// *************************************************************************** *
// *                                                                           *
// *                      Mentor Graphics Corporation                          *
// *                          All rights reserved                              *
// *                                                                           *
// *************************************************************************** *
// *                                                                           *
// * Description:         CANDB File                                           *
// * Generated at:        2021-02-26 13:32                                     *
// * System:              SPA4710_Final2                                       *
// * Variant:             ConfigurationsSPA3AD                                 *
// * Network:             Mid3Can                                              *
// *                                                                           *
// *************************************************************************** *
// *                                                                           *
// *             THIS CONFIGURATION MIGHT CONTAIN SOME ERRORS                  *
// *              IF THE INPUT MODEL WAS NOT PROPERLY FORMED!                  *
// *                    Do Not Use this File directly!                         *
// *                                                                           *
// *************************************************************************** *
VERSION "Mid3Can"

NS_ :

BS_ :

BU_ :  ETC SSM VCU1 VIM VIMB

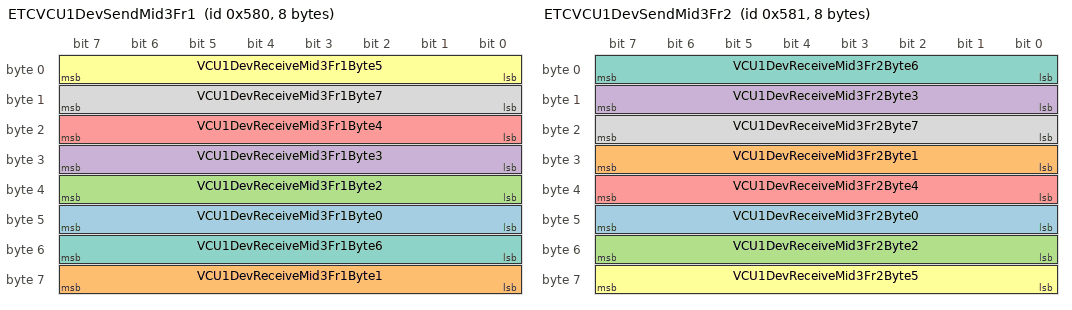
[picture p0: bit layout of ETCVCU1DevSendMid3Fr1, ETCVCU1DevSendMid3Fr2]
BO_ 1408 ETCVCU1DevSendMid3Fr1 : 8 ETC
 SG_ VCU1DevReceiveMid3Fr1Byte0 : 47|8@0+ (1.0,0.0) [0.0|255.0] "Unitless" VCU1
 SG_ VCU1DevReceiveMid3Fr1Byte1 : 63|8@0+ (1.0,0.0) [0.0|255.0] "Unitless" VCU1
 SG_ VCU1DevReceiveMid3Fr1Byte2 : 39|8@0+ (1.0,0.0) [0.0|255.0] "Unitless" VCU1
 SG_ VCU1DevReceiveMid3Fr1Byte3 : 31|8@0+ (1.0,0.0) [0.0|255.0] "Unitless" VCU1
 SG_ VCU1DevReceiveMid3Fr1Byte4 : 23|8@0+ (1.0,0.0) [0.0|255.0] "Unitless" VCU1
 SG_ VCU1DevReceiveMid3Fr1Byte5 : 7|8@0+ (1.0,0.0) [0.0|255.0] "Unitless" VCU1
 SG_ VCU1DevReceiveMid3Fr1Byte6 : 55|8@0+ (1.0,0.0) [0.0|255.0] "Unitless" VCU1
 SG_ VCU1DevReceiveMid3Fr1Byte7 : 15|8@0+ (1.0,0.0) [0.0|255.0] "Unitless" VCU1

BO_ 1409 ETCVCU1DevSendMid3Fr2 : 8 ETC
 SG_ VCU1DevReceiveMid3Fr2Byte0 : 47|8@0+ (1.0,0.0) [0.0|255.0] "Unitless" VCU1
 SG_ VCU1DevReceiveMid3Fr2Byte1 : 31|8@0+ (1.0,0.0) [0.0|255.0] "Unitless" VCU1
 SG_ VCU1DevReceiveMid3Fr2Byte2 : 55|8@0+ (1.0,0.0) [0.0|255.0] "Unitless" VCU1
 SG_ VCU1DevReceiveMid3Fr2Byte3 : 15|8@0+ (1.0,0.0) [0.0|255.0] "Unitless" VCU1
 SG_ VCU1DevReceiveMid3Fr2Byte4 : 39|8@0+ (1.0,0.0) [0.0|255.0] "Unitless" VCU1
 SG_ VCU1DevReceiveMid3Fr2Byte5 : 63|8@0+ (1.0,0.0) [0.0|255.0] "Unitless" VCU1
 SG_ VCU1DevReceiveMid3Fr2Byte6 : 7|8@0+ (1.0,0.0) [0.0|255.0] "Unitless" VCU1
 SG_ VCU1DevReceiveMid3Fr2Byte7 : 23|8@0+ (1.0,0.0) [0.0|255.0] "Unitless" VCU1

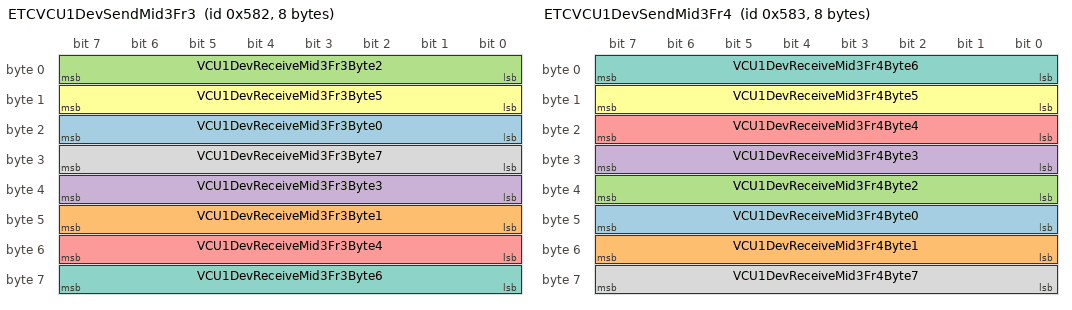
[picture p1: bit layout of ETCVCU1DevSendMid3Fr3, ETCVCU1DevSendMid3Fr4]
BO_ 1410 ETCVCU1DevSendMid3Fr3 : 8 ETC
 SG_ VCU1DevReceiveMid3Fr3Byte0 : 23|8@0+ (1.0,0.0) [0.0|255.0] "Unitless" VCU1
 SG_ VCU1DevReceiveMid3Fr3Byte1 : 47|8@0+ (1.0,0.0) [0.0|255.0] "Unitless" VCU1
 SG_ VCU1DevReceiveMid3Fr3Byte2 : 7|8@0+ (1.0,0.0) [0.0|255.0] "Unitless" VCU1
 SG_ VCU1DevReceiveMid3Fr3Byte3 : 39|8@0+ (1.0,0.0) [0.0|255.0] "Unitless" VCU1
 SG_ VCU1DevReceiveMid3Fr3Byte4 : 55|8@0+ (1.0,0.0) [0.0|255.0] "Unitless" VCU1
 SG_ VCU1DevReceiveMid3Fr3Byte5 : 15|8@0+ (1.0,0.0) [0.0|255.0] "Unitless" VCU1
 SG_ VCU1DevReceiveMid3Fr3Byte6 : 63|8@0+ (1.0,0.0) [0.0|255.0] "Unitless" VCU1
 SG_ VCU1DevReceiveMid3Fr3Byte7 : 31|8@0+ (1.0,0.0) [0.0|255.0] "Unitless" VCU1

BO_ 1411 ETCVCU1DevSendMid3Fr4 : 8 ETC
 SG_ VCU1DevReceiveMid3Fr4Byte0 : 47|8@0+ (1.0,0.0) [0.0|255.0] "Unitless" VCU1
 SG_ VCU1DevReceiveMid3Fr4Byte1 : 55|8@0+ (1.0,0.0) [0.0|255.0] "Unitless" VCU1
 SG_ VCU1DevReceiveMid3Fr4Byte2 : 39|8@0+ (1.0,0.0) [0.0|255.0] "Unitless" VCU1
 SG_ VCU1DevReceiveMid3Fr4Byte3 : 31|8@0+ (1.0,0.0) [0.0|255.0] "Unitless" VCU1
 SG_ VCU1DevReceiveMid3Fr4Byte4 : 23|8@0+ (1.0,0.0) [0.0|255.0] "Unitless" VCU1
 SG_ VCU1DevReceiveMid3Fr4Byte5 : 15|8@0+ (1.0,0.0) [0.0|255.0] "Unitless" VCU1
 SG_ VCU1DevReceiveMid3Fr4Byte6 : 7|8@0+ (1.0,0.0) [0.0|255.0] "Unitless" VCU1
 SG_ VCU1DevReceiveMid3Fr4Byte7 : 63|8@0+ (1.0,0.0) [0.0|255.0] "Unitless" VCU1

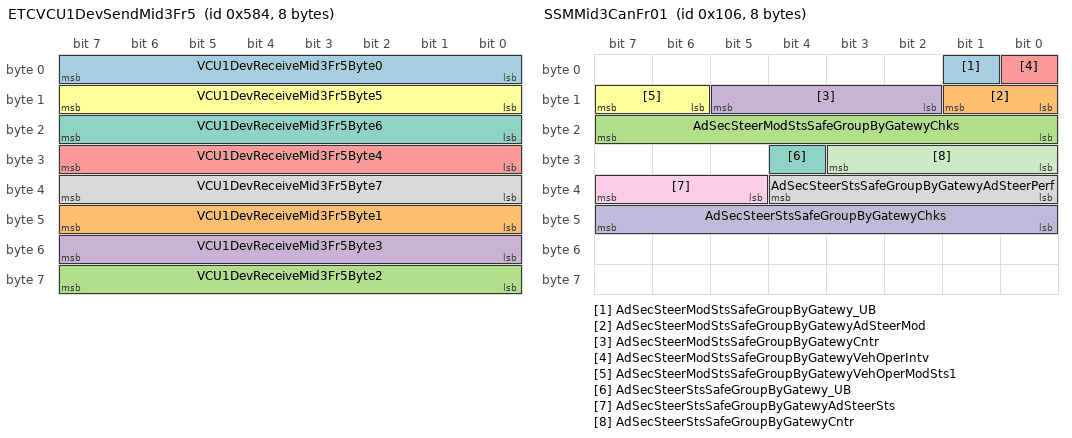
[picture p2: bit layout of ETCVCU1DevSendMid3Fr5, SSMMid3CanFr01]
BO_ 1412 ETCVCU1DevSendMid3Fr5 : 8 ETC
 SG_ VCU1DevReceiveMid3Fr5Byte0 : 7|8@0+ (1.0,0.0) [0.0|255.0] "Unitless" VCU1
 SG_ VCU1DevReceiveMid3Fr5Byte1 : 47|8@0+ (1.0,0.0) [0.0|255.0] "Unitless" VCU1
 SG_ VCU1DevReceiveMid3Fr5Byte2 : 63|8@0+ (1.0,0.0) [0.0|255.0] "Unitless" VCU1
 SG_ VCU1DevReceiveMid3Fr5Byte3 : 55|8@0+ (1.0,0.0) [0.0|255.0] "Unitless" VCU1
 SG_ VCU1DevReceiveMid3Fr5Byte4 : 31|8@0+ (1.0,0.0) [0.0|255.0] "Unitless" VCU1
 SG_ VCU1DevReceiveMid3Fr5Byte5 : 15|8@0+ (1.0,0.0) [0.0|255.0] "Unitless" VCU1
 SG_ VCU1DevReceiveMid3Fr5Byte6 : 23|8@0+ (1.0,0.0) [0.0|255.0] "Unitless" VCU1
 SG_ VCU1DevReceiveMid3Fr5Byte7 : 39|8@0+ (1.0,0.0) [0.0|255.0] "Unitless" VCU1

BO_ 262 SSMMid3CanFr01 : 8 SSM
 SG_ AdSecSteerModStsSafeGroupByGatewy_UB : 1|1@0+ (1,0) [0|1] "" VCU1
 SG_ AdSecSteerModStsSafeGroupByGatewyAdSteerMod : 9|2@0+ (1,0) [0|3] "" VCU1
 SG_ AdSecSteerModStsSafeGroupByGatewyChks : 23|8@0+ (1.0,0.0) [0.0|255.0] "Unitless" VCU1
 SG_ AdSecSteerModStsSafeGroupByGatewyCntr : 13|4@0+ (1.0,0.0) [0.0|15.0] "Unitless" VCU1
 SG_ AdSecSteerModStsSafeGroupByGatewyVehOperIntv : 0|1@0+ (1,0) [0|1] "" VCU1
 SG_ AdSecSteerModStsSafeGroupByGatewyVehOperModSts1 : 15|2@0+ (1,0) [0|3] "" VCU1
 SG_ AdSecSteerStsSafeGroupByGatewy_UB : 28|1@0+ (1,0) [0|1] "" VCU1
 SG_ AdSecSteerStsSafeGroupByGatewyAdSteerPerf : 36|5@0+ (1,0) [0|31] "" VCU1
 SG_ AdSecSteerStsSafeGroupByGatewyAdSteerSts : 39|3@0+ (1,0) [0|7] "" VCU1
 SG_ AdSecSteerStsSafeGroupByGatewyChks : 47|8@0+ (1.0,0.0) [0.0|255.0] "Unitless" VCU1
 SG_ AdSecSteerStsSafeGroupByGatewyCntr : 27|4@0+ (1.0,0.0) [0.0|15.0] "Unitless" VCU1

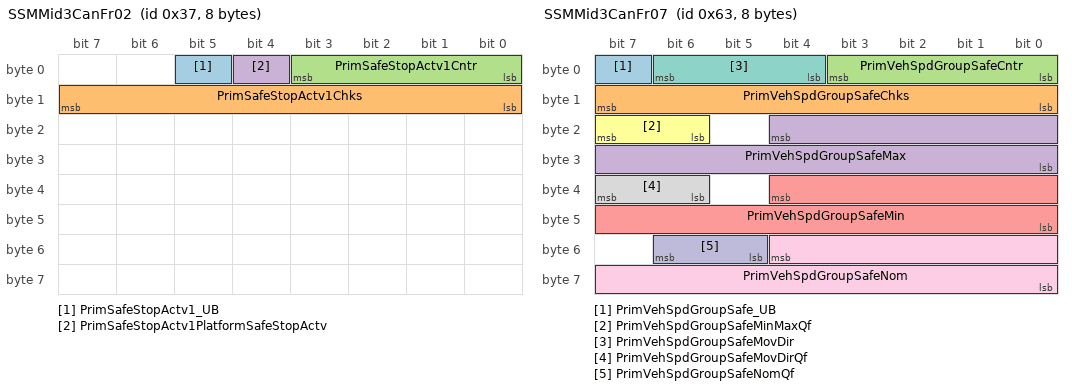
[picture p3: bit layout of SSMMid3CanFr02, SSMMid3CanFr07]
BO_ 55 SSMMid3CanFr02 : 8 SSM
 SG_ PrimSafeStopActv1_UB : 5|1@0+ (1,0) [0|1] "" VCU1
 SG_ PrimSafeStopActv1Chks : 15|8@0+ (1.0,0.0) [0.0|255.0] "Unitless" VCU1
 SG_ PrimSafeStopActv1Cntr : 3|4@0+ (1.0,0.0) [0.0|15.0] "Unitless" VCU1
 SG_ PrimSafeStopActv1PlatformSafeStopActv : 4|1@0+ (1,0) [0|1] "" VCU1

BO_ 99 SSMMid3CanFr07 : 8 SSM
 SG_ PrimVehSpdGroupSafe_UB : 7|1@0+ (1,0) [0|1] "" VCU1,VIM
 SG_ PrimVehSpdGroupSafeChks : 15|8@0+ (1.0,0.0) [0.0|255.0] "Unitless" VCU1,VIM
 SG_ PrimVehSpdGroupSafeCntr : 3|4@0+ (1.0,0.0) [0.0|15.0] "Unitless" VCU1,VIM
 SG_ PrimVehSpdGroupSafeMax : 20|13@0+ (0.01,0.0) [0.0|81.91] "m/s" VCU1,VIM
 SG_ PrimVehSpdGroupSafeMin : 36|13@0+ (0.01,0.0) [0.0|81.91] "m/s" VCU1,VIM
 SG_ PrimVehSpdGroupSafeMinMaxQf : 23|2@0+ (1,0) [0|3] "" VCU1,VIM
 SG_ PrimVehSpdGroupSafeMovDir : 6|3@0+ (1,0) [0|7] "" VCU1,VIM
 SG_ PrimVehSpdGroupSafeMovDirQf : 39|2@0+ (1,0) [0|3] "" VCU1,VIM
 SG_ PrimVehSpdGroupSafeNom : 52|13@0+ (0.01,0.0) [0.0|81.91] "m/s" VCU1,VIM
 SG_ PrimVehSpdGroupSafeNomQf : 54|2@0+ (1,0) [0|3] "" VCU1,VIM

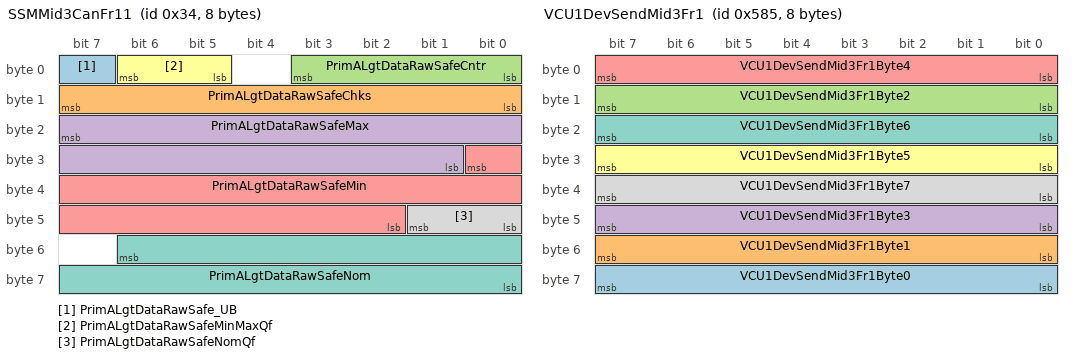
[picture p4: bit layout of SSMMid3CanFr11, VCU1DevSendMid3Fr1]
BO_ 52 SSMMid3CanFr11 : 8 SSM
 SG_ PrimALgtDataRawSafe_UB : 7|1@0+ (1,0) [0|1] "" VCU1,VIM
 SG_ PrimALgtDataRawSafeChks : 15|8@0+ (1.0,0.0) [0.0|255.0] "Unitless" VCU1,VIM
 SG_ PrimALgtDataRawSafeCntr : 3|4@0+ (1.0,0.0) [0.0|15.0] "Unitless" VCU1,VIM
 SG_ PrimALgtDataRawSafeMax : 23|15@0+ (0.001,-16.384) [-16.384|16.383000000000003] "m/s^2" VCU1,VIM
 SG_ PrimALgtDataRawSafeMin : 24|15@0+ (0.001,-16.384) [-16.384|16.383000000000003] "m/s^2" VCU1,VIM
 SG_ PrimALgtDataRawSafeMinMaxQf : 6|2@0+ (1,0) [0|3] "" VCU1,VIM
 SG_ PrimALgtDataRawSafeNom : 54|15@0+ (0.001,-16.384) [-16.384|16.383000000000003] "m/s^2" VCU1,VIM
 SG_ PrimALgtDataRawSafeNomQf : 41|2@0+ (1,0) [0|3] "" VCU1,VIM

BO_ 1287 SsmMid3CanNmFr : 8 SSM
 SG_ Body_SSM : 21|1@0+ (1,0) [0|0] "" VIM
 SG_ Brake_SSM : 33|1@0+ (1,0) [0|0] "" VIM
 SG_ Diesel_SSM : 32|1@0+ (1,0) [0|0] "" VIM
 SG_ Hazard_SSM : 18|1@0+ (1,0) [0|0] "" VIM
 SG_ InfotainmentAndHMI_SSM : 22|1@0+ (1,0) [0|0] "" VIM
 SG_ PNCCharging_SSM : 25|1@0+ (1,0) [0|0] "" VIM
 SG_ PNCDriverinfo_SSM : 16|1@0+ (1,0) [0|0] "" VIM
 SG_ PNCDriverinfoPoll_SSM : 31|1@0+ (1,0) [0|0] "" VIM
 SG_ PNCDriving_SSM : 27|1@0+ (1,0) [0|0] "" VIM
 SG_ PNCEntrance_SSM : 23|1@0+ (1,0) [0|0] "" VIM
 SG_ PNCGlobal_SSM : 29|1@0+ (1,0) [0|0] "" VIM
 SG_ PNCGSD_SSM : 30|1@0+ (1,0) [0|0] "" VIM
 SG_ PNCHVEnergyStorage_SSM : 35|1@0+ (1,0) [0|0] "" VIM
 SG_ PNCLocking_SSM : 17|1@0+ (1,0) [0|0] "" VIM
 SG_ PNCPreClimatization_SSM : 26|1@0+ (1,0) [0|0] "" VIM
 SG_ PNCSpare1_SSM : 39|1@0+ (1,0) [0|0] "" VIM
 SG_ PNCSpare2_SSM : 38|1@0+ (1,0) [0|0] "" VIM
 SG_ PNCSpare3_SSM : 37|1@0+ (1,0) [0|0] "" VIM
 SG_ PNCSpare4_SSM : 36|1@0+ (1,0) [0|0] "" VIM
 SG_ PNCStart_SSM : 24|1@0+ (1,0) [0|0] "" VIM
 SG_ PNCTrailerCaravan_SSM : 28|1@0+ (1,0) [0|0] "" VIM
 SG_ VehicleAPI_SSM : 34|1@0+ (1,0) [0|0] "" VIM
 SG_ Visibility_SSM : 20|1@0+ (1,0) [0|0] "" VIM
 SG_ WarningSounds_SSM : 19|1@0+ (1,0) [0|0] "" VIM
 SG_ NM_PNI_SSM : 14|1@0+ (1,0) [0|0] "" VIM
 SG_ NM_AW_SSM : 12|1@0+ (1,0) [0|0] "" VIM
 SG_ NM_CS_SSM : 11|1@0+ (1,0) [0|0] "" VIM
 SG_ NM_RMR_SSM : 8|1@0+ (1,0) [0|0] "" VIM
 SG_ NM_NodeID_SSM : 7|8@0+ (1,0) [0|0] "" VIM

BO_ 1413 VCU1DevSendMid3Fr1 : 8 VCU1
 SG_ VCU1DevSendMid3Fr1Byte0 : 63|8@0+ (1.0,0.0) [0.0|255.0] "Unitless" ETC
 SG_ VCU1DevSendMid3Fr1Byte1 : 55|8@0+ (1.0,0.0) [0.0|255.0] "Unitless" ETC
 SG_ VCU1DevSendMid3Fr1Byte2 : 15|8@0+ (1.0,0.0) [0.0|255.0] "Unitless" ETC
 SG_ VCU1DevSendMid3Fr1Byte3 : 47|8@0+ (1.0,0.0) [0.0|255.0] "Unitless" ETC
 SG_ VCU1DevSendMid3Fr1Byte4 : 7|8@0+ (1.0,0.0) [0.0|255.0] "Unitless" ETC
 SG_ VCU1DevSendMid3Fr1Byte5 : 31|8@0+ (1.0,0.0) [0.0|255.0] "Unitless" ETC
 SG_ VCU1DevSendMid3Fr1Byte6 : 23|8@0+ (1.0,0.0) [0.0|255.0] "Unitless" ETC
 SG_ VCU1DevSendMid3Fr1Byte7 : 39|8@0+ (1.0,0.0) [0.0|255.0] "Unitless" ETC

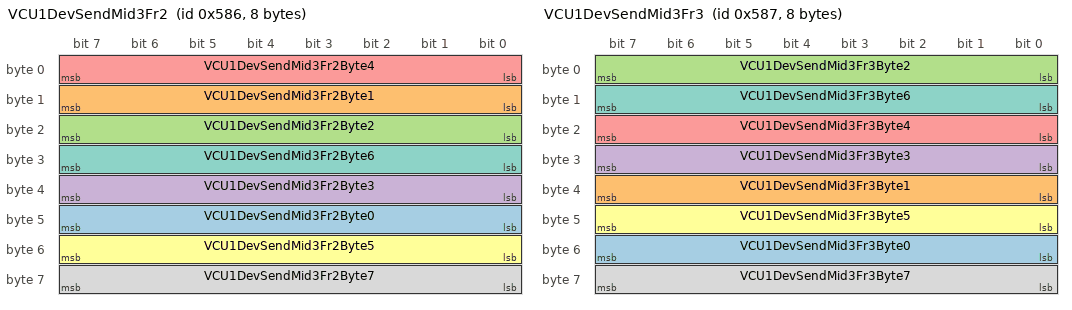
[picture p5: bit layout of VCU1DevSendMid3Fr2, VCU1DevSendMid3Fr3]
BO_ 1414 VCU1DevSendMid3Fr2 : 8 VCU1
 SG_ VCU1DevSendMid3Fr2Byte0 : 47|8@0+ (1.0,0.0) [0.0|255.0] "Unitless" ETC
 SG_ VCU1DevSendMid3Fr2Byte1 : 15|8@0+ (1.0,0.0) [0.0|255.0] "Unitless" ETC
 SG_ VCU1DevSendMid3Fr2Byte2 : 23|8@0+ (1.0,0.0) [0.0|255.0] "Unitless" ETC
 SG_ VCU1DevSendMid3Fr2Byte3 : 39|8@0+ (1.0,0.0) [0.0|255.0] "Unitless" ETC
 SG_ VCU1DevSendMid3Fr2Byte4 : 7|8@0+ (1.0,0.0) [0.0|255.0] "Unitless" ETC
 SG_ VCU1DevSendMid3Fr2Byte5 : 55|8@0+ (1.0,0.0) [0.0|255.0] "Unitless" ETC
 SG_ VCU1DevSendMid3Fr2Byte6 : 31|8@0+ (1.0,0.0) [0.0|255.0] "Unitless" ETC
 SG_ VCU1DevSendMid3Fr2Byte7 : 63|8@0+ (1.0,0.0) [0.0|255.0] "Unitless" ETC

BO_ 1415 VCU1DevSendMid3Fr3 : 8 VCU1
 SG_ VCU1DevSendMid3Fr3Byte0 : 55|8@0+ (1.0,0.0) [0.0|255.0] "Unitless" ETC
 SG_ VCU1DevSendMid3Fr3Byte1 : 39|8@0+ (1.0,0.0) [0.0|255.0] "Unitless" ETC
 SG_ VCU1DevSendMid3Fr3Byte2 : 7|8@0+ (1.0,0.0) [0.0|255.0] "Unitless" ETC
 SG_ VCU1DevSendMid3Fr3Byte3 : 31|8@0+ (1.0,0.0) [0.0|255.0] "Unitless" ETC
 SG_ VCU1DevSendMid3Fr3Byte4 : 23|8@0+ (1.0,0.0) [0.0|255.0] "Unitless" ETC
 SG_ VCU1DevSendMid3Fr3Byte5 : 47|8@0+ (1.0,0.0) [0.0|255.0] "Unitless" ETC
 SG_ VCU1DevSendMid3Fr3Byte6 : 15|8@0+ (1.0,0.0) [0.0|255.0] "Unitless" ETC
 SG_ VCU1DevSendMid3Fr3Byte7 : 63|8@0+ (1.0,0.0) [0.0|255.0] "Unitless" ETC

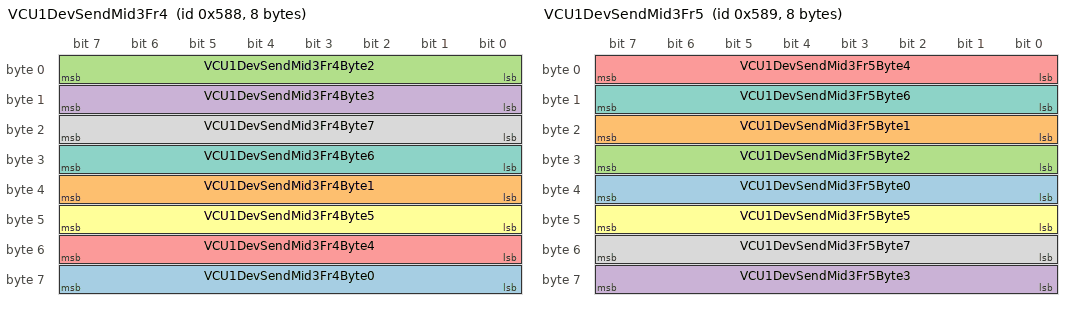
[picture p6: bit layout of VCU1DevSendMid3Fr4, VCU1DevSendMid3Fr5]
BO_ 1416 VCU1DevSendMid3Fr4 : 8 VCU1
 SG_ VCU1DevSendMid3Fr4Byte0 : 63|8@0+ (1.0,0.0) [0.0|255.0] "Unitless" ETC
 SG_ VCU1DevSendMid3Fr4Byte1 : 39|8@0+ (1.0,0.0) [0.0|255.0] "Unitless" ETC
 SG_ VCU1DevSendMid3Fr4Byte2 : 7|8@0+ (1.0,0.0) [0.0|255.0] "Unitless" ETC
 SG_ VCU1DevSendMid3Fr4Byte3 : 15|8@0+ (1.0,0.0) [0.0|255.0] "Unitless" ETC
 SG_ VCU1DevSendMid3Fr4Byte4 : 55|8@0+ (1.0,0.0) [0.0|255.0] "Unitless" ETC
 SG_ VCU1DevSendMid3Fr4Byte5 : 47|8@0+ (1.0,0.0) [0.0|255.0] "Unitless" ETC
 SG_ VCU1DevSendMid3Fr4Byte6 : 31|8@0+ (1.0,0.0) [0.0|255.0] "Unitless" ETC
 SG_ VCU1DevSendMid3Fr4Byte7 : 23|8@0+ (1.0,0.0) [0.0|255.0] "Unitless" ETC

BO_ 1417 VCU1DevSendMid3Fr5 : 8 VCU1
 SG_ VCU1DevSendMid3Fr5Byte0 : 39|8@0+ (1.0,0.0) [0.0|255.0] "Unitless" ETC
 SG_ VCU1DevSendMid3Fr5Byte1 : 23|8@0+ (1.0,0.0) [0.0|255.0] "Unitless" ETC
 SG_ VCU1DevSendMid3Fr5Byte2 : 31|8@0+ (1.0,0.0) [0.0|255.0] "Unitless" ETC
 SG_ VCU1DevSendMid3Fr5Byte3 : 63|8@0+ (1.0,0.0) [0.0|255.0] "Unitless" ETC
 SG_ VCU1DevSendMid3Fr5Byte4 : 7|8@0+ (1.0,0.0) [0.0|255.0] "Unitless" ETC
 SG_ VCU1DevSendMid3Fr5Byte5 : 47|8@0+ (1.0,0.0) [0.0|255.0] "Unitless" ETC
 SG_ VCU1DevSendMid3Fr5Byte6 : 15|8@0+ (1.0,0.0) [0.0|255.0] "Unitless" ETC
 SG_ VCU1DevSendMid3Fr5Byte7 : 55|8@0+ (1.0,0.0) [0.0|255.0] "Unitless" ETC

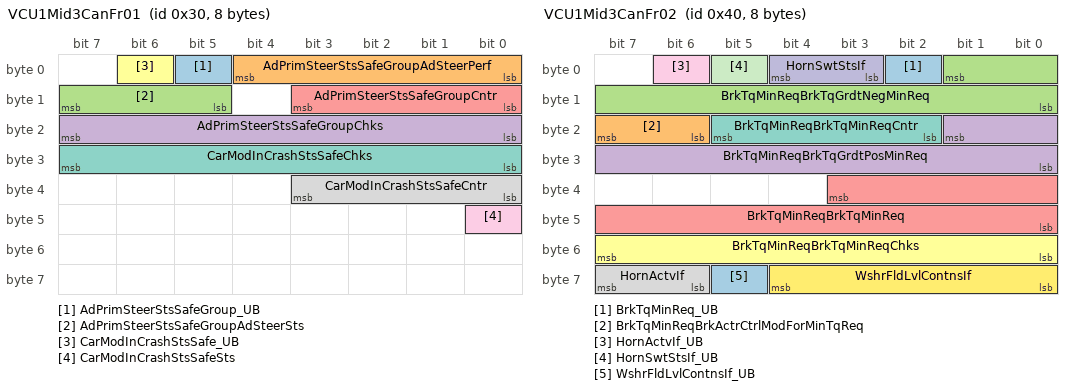
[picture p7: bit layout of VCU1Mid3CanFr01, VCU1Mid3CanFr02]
BO_ 48 VCU1Mid3CanFr01 : 8 VCU1
 SG_ AdPrimSteerStsSafeGroup_UB : 5|1@0+ (1,0) [0|1] "" VIM
 SG_ AdPrimSteerStsSafeGroupAdSteerPerf : 4|5@0+ (1,0) [0|31] "" VIM
 SG_ AdPrimSteerStsSafeGroupAdSteerSts : 15|3@0+ (1,0) [0|7] "" VIM
 SG_ AdPrimSteerStsSafeGroupChks : 23|8@0+ (1.0,0.0) [0.0|255.0] "Unitless" VIM
 SG_ AdPrimSteerStsSafeGroupCntr : 11|4@0+ (1.0,0.0) [0.0|15.0] "Unitless" VIM
 SG_ CarModInCrashStsSafe_UB : 6|1@0+ (1,0) [0|1] "" VIM,VIMB
 SG_ CarModInCrashStsSafeChks : 24|8@1+ (1.0,0.0) [0.0|255.0] "Unitless" VIM,VIMB
 SG_ CarModInCrashStsSafeCntr : 32|4@1+ (1.0,0.0) [0.0|15.0] "Unitless" VIM,VIMB
 SG_ CarModInCrashStsSafeSts : 40|1@1+ (1,0) [0|1] "" VIM,VIMB

BO_ 64 VCU1Mid3CanFr02 : 8 VCU1
 SG_ BrkTqMinReq_UB : 2|1@0+ (1,0) [0|1] "" SSM
 SG_ BrkTqMinReqBrkActrCtrlModForMinTqReq : 23|2@0+ (1,0) [0|3] "" SSM
 SG_ BrkTqMinReqBrkTqGrdtNegMinReq : 1|10@0+ (500.0,0.0) [0.0|511500.0] "Nm/s" SSM
 SG_ BrkTqMinReqBrkTqGrdtPosMinReq : 17|10@0+ (500.0,0.0) [0.0|511500.0] "Nm/s" SSM
 SG_ BrkTqMinReqBrkTqMinReq : 35|12@0+ (4.0,0.0) [0.0|16380.0] "Nm" SSM
 SG_ BrkTqMinReqBrkTqMinReqChks : 55|8@0+ (1.0,0.0) [0.0|255.0] "Unitless" SSM
 SG_ BrkTqMinReqBrkTqMinReqCntr : 21|4@0+ (1.0,0.0) [0.0|15.0] "Unitless" SSM
 SG_ HornActvIf : 63|2@0+ (1,0) [0|3] "" VIM,VIMB
 SG_ HornActvIf_UB : 6|1@0+ (1,0) [0|1] "" VIM,VIMB
 SG_ HornSwtStsIf : 4|2@0+ (1,0) [0|3] "" VIM,VIMB
 SG_ HornSwtStsIf_UB : 5|1@0+ (1,0) [0|1] "" VIM,VIMB
 SG_ WshrFldLvlContnsIf : 60|5@0+ (1.0,0.0) [0.0|31.0] "Unitless" VIM,VIMB
 SG_ WshrFldLvlContnsIf_UB : 61|1@0+ (1,0) [0|1] "" VIM,VIMB

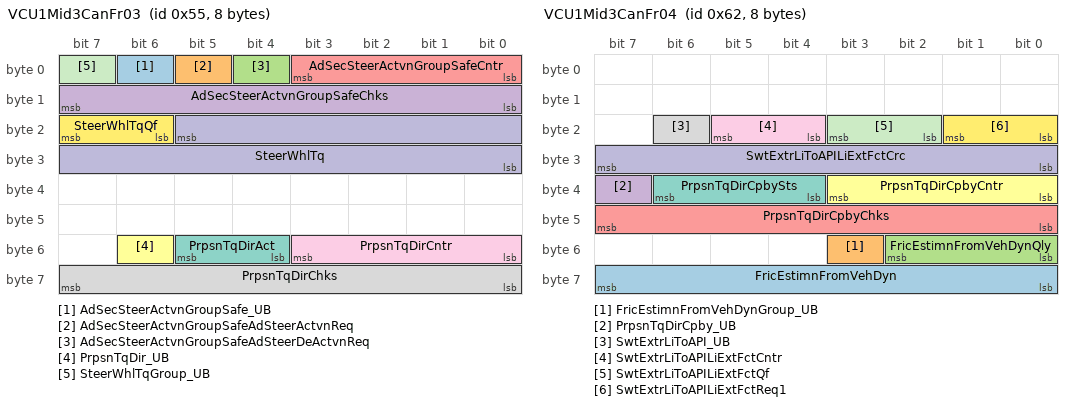
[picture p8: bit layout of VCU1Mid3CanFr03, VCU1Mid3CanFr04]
BO_ 85 VCU1Mid3CanFr03 : 8 VCU1
 SG_ AdSecSteerActvnGroupSafe_UB : 6|1@0+ (1,0) [0|1] "" SSM
 SG_ AdSecSteerActvnGroupSafeAdSteerActvnReq : 5|1@0+ (1,0) [0|1] "" SSM
 SG_ AdSecSteerActvnGroupSafeAdSteerDeActvnReq : 4|1@0+ (1,0) [0|1] "" SSM
 SG_ AdSecSteerActvnGroupSafeChks : 15|8@0+ (1.0,0.0) [0.0|255.0] "Unitless" SSM
 SG_ AdSecSteerActvnGroupSafeCntr : 3|4@0+ (1.0,0.0) [0.0|15.0] "Unitless" SSM
 SG_ PrpsnTqDir_UB : 54|1@0+ (1,0) [0|1] "" VIM,VIMB
 SG_ PrpsnTqDirAct : 53|2@0+ (1,0) [0|3] "" VIM,VIMB
 SG_ PrpsnTqDirChks : 63|8@0+ (1.0,0.0) [0.0|255.0] "Unitless" VIM,VIMB
 SG_ PrpsnTqDirCntr : 51|4@0+ (1.0,0.0) [0.0|15.0] "Unitless" VIM,VIMB
 SG_ SteerWhlTq : 21|14@0- (0.00390625,0.0) [-30.0|30.0] "NewtonMeter" VIM,VIMB
 SG_ SteerWhlTqGroup_UB : 7|1@0+ (1,0) [0|1] "" VIM,VIMB
 SG_ SteerWhlTqQf : 23|2@0+ (1,0) [0|3] "" VIM,VIMB

BO_ 98 VCU1Mid3CanFr04 : 8 VCU1
 SG_ FricEstimnFromVehDyn : 63|8@0+ (0.01,0.0) [0.0|2.0] "Unitless" SSM,VIM,VIMB
 SG_ FricEstimnFromVehDynGroup_UB : 51|1@0+ (1,0) [0|1] "" SSM,VIM,VIMB
 SG_ FricEstimnFromVehDynQly : 50|3@0+ (1,0) [0|7] "" SSM,VIM,VIMB
 SG_ PrpsnTqDirCpby_UB : 39|1@0+ (1,0) [0|1] "" VIM,VIMB
 SG_ PrpsnTqDirCpbyChks : 47|8@0+ (1.0,0.0) [0.0|255.0] "Unitless" VIM,VIMB
 SG_ PrpsnTqDirCpbyCntr : 35|4@0+ (1.0,0.0) [0.0|15.0] "Unitless" VIM,VIMB
 SG_ PrpsnTqDirCpbySts : 38|3@0+ (1,0) [0|7] "" VIM,VIMB
 SG_ SwtExtrLiToAPI_UB : 22|1@0+ (1,0) [0|1] "" VIM,VIMB
 SG_ SwtExtrLiToAPILiExtFctCntr : 21|2@0+ (1.0,0.0) [0.0|3.0] "Unitless" VIM,VIMB
 SG_ SwtExtrLiToAPILiExtFctCrc : 31|8@0+ (1.0,0.0) [0.0|255.0] "Unitless" VIM,VIMB
 SG_ SwtExtrLiToAPILiExtFctQf : 19|2@0+ (1,0) [0|3] "" VIM,VIMB
 SG_ SwtExtrLiToAPILiExtFctReq1 : 17|2@0+ (1,0) [0|3] "" VIM,VIMB

BO_ 153 VCU1Mid3CanFr05 : 8 VCU1
 SG_ AdSecBlindStopMonActvnGroupSafe_UB : 54|1@0+ (1,0) [0|1] "" SSM
 SG_ AdSecBlindStopMonActvnGroupSafeActvnReq : 53|1@0+ (1,0) [0|1] "" SSM
 SG_ AdSecBlindStopMonActvnGroupSafeChks : 63|8@0+ (1.0,0.0) [0.0|255.0] "Unitless" SSM
 SG_ AdSecBlindStopMonActvnGroupSafeCntr : 51|4@0+ (1.0,0.0) [0.0|15.0] "Unitless" SSM
 SG_ AdSecBlindStopMonActvnGroupSafeDeactvnReq : 52|1@0+ (1,0) [0|1] "" SSM
 SG_ DrvrGearShiftManReq_UB : 5|1@0+ (1,0) [0|1] "" VIM,VIMB
 SG_ DrvrGearShiftManReqDwnTipReq : 0|1@0+ (1,0) [0|1] "" VIM,VIMB
 SG_ DrvrGearShiftManReqSteerWhlDwnReq : 1|1@0+ (1,0) [0|1] "" VIM,VIMB
 SG_ DrvrGearShiftManReqSteerWhlUpReq : 2|1@0+ (1,0) [0|1] "" VIM,VIMB
 SG_ DrvrGearShiftManReqTipReq : 3|1@0+ (1,0) [0|1] "" VIM,VIMB
 SG_ DrvrGearShiftManReqUpTipReq : 4|1@0+ (1,0) [0|1] "" VIM,VIMB
 SG_ PassSeatSts : 41|2@0+ (1,0) [0|3] "" VIM,VIMB
 SG_ PassSeatSts_UB : 42|1@0+ (1,0) [0|1] "" VIM,VIMB
 SG_ SnsrClngErrIf_UB : 6|1@0+ (1,0) [0|1] "" VIM,VIMB
 SG_ SnsrClngErrIfActr1 : 15|1@0+ (1,0) [0|1] "" VIM,VIMB
 SG_ SnsrClngErrIfActr2 : 14|1@0+ (1,0) [0|1] "" VIM,VIMB
 SG_ SnsrClngErrIfActr3 : 13|1@0+ (1,0) [0|1] "" VIM,VIMB
 SG_ SnsrClngErrIfRsvd1 : 12|1@0+ (1,0) [0|1] "" VIM,VIMB
 SG_ SnsrClngErrIfRsvd2 : 11|1@0+ (1,0) [0|1] "" VIM,VIMB
 SG_ SnsrClngErrIfRsvd3 : 10|1@0+ (1,0) [0|1] "" VIM,VIMB
 SG_ SnsrClngErrIfSysClngFailr : 9|1@0+ (1,0) [0|1] "" VIM,VIMB
 SG_ SnsrClngErrIfWshrFldSnsrFailr : 8|1@0+ (1,0) [0|1] "" VIM,VIMB
 SG_ VehM : 29|14@0+ (1.0,0.0) [0.0|10000.0] "kg" SSM,VIM,VIMB
 SG_ VehMGroup_UB : 7|1@0+ (1,0) [0|1] "" SSM,VIM,VIMB
 SG_ VehMNomTrlrM : 31|2@0+ (1,0) [0|3] "" SSM,VIM,VIMB
 SG_ VehMQly : 17|2@0+ (1,0) [0|3] "" SSM,VIM,VIMB
 SG_ WinWipgAutCmdIf : 20|3@0+ (1,0) [0|7] "" VIM,VIMB
 SG_ WinWipgAutCmdIf_UB : 21|1@0+ (1,0) [0|1] "" VIM,VIMB
 SG_ WipgFrntAutModIf : 46|2@0+ (1,0) [0|3] "" VIM,VIMB
 SG_ WipgFrntAutModIf_UB : 47|1@0+ (1,0) [0|1] "" VIM,VIMB
 SG_ WiprActvIf : 22|1@0+ (1,0) [0|1] "" VIM,VIMB
 SG_ WiprActvIf_UB : 23|1@0+ (1,0) [0|1] "" VIM,VIMB
 SG_ WshngCycActvIf : 43|1@0+ (1,0) [0|1] "" VIM,VIMB
 SG_ WshngCycActvIf_UB : 44|1@0+ (1,0) [0|1] "" VIM,VIMB

BO_ 896 VCU1Mid3CanFr06 : 8 VCU1
 SG_ CarTiGlb : 7|32@0+ (0.1,0.0) [0.0|429496729.5] "s" SSM
 SG_ CarTiGlb_UB : 39|1@0+ (1,0) [0|1] "" SSM

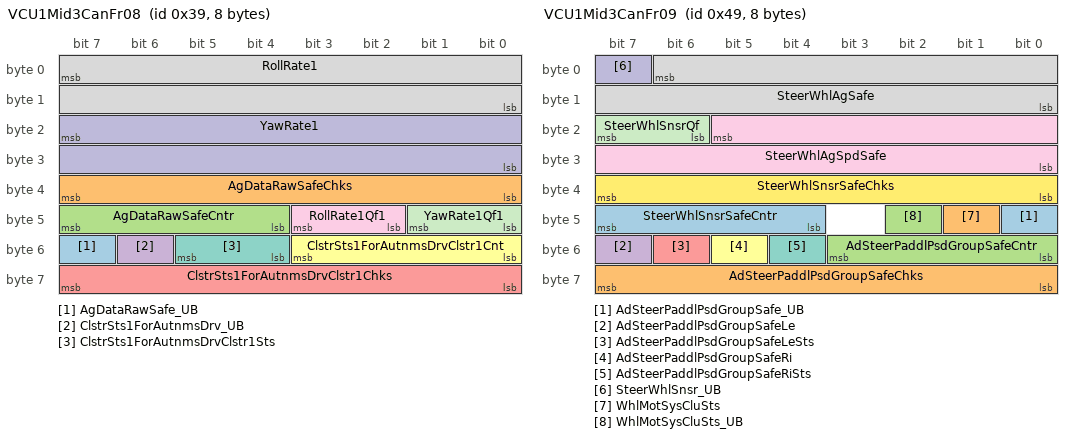
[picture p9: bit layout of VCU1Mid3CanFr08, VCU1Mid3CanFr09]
BO_ 57 VCU1Mid3CanFr08 : 8 VCU1
 SG_ AgDataRawSafe_UB : 55|1@0+ (1,0) [0|1] "" SSM
 SG_ AgDataRawSafeChks : 39|8@0+ (1.0,0.0) [0.0|255.0] "Unitless" SSM
 SG_ AgDataRawSafeCntr : 47|4@0+ (1.0,0.0) [0.0|15.0] "Unitless" SSM
 SG_ ClstrSts1ForAutnmsDrv_UB : 54|1@0+ (1,0) [0|1] "" SSM,VIM,VIMB
 SG_ ClstrSts1ForAutnmsDrvClstr1Chks : 63|8@0+ (1.0,0.0) [0.0|255.0] "Unitless" SSM,VIM,VIMB
 SG_ ClstrSts1ForAutnmsDrvClstr1Cnt : 51|4@0+ (1.0,0.0) [0.0|15.0] "Unitless" SSM,VIM,VIMB
 SG_ ClstrSts1ForAutnmsDrvClstr1Sts : 53|2@0+ (1,0) [0|3] "" SSM,VIM,VIMB
 SG_ RollRate1 : 7|16@0- (0.000244140625,0.0) [-6.0|6.0] "rad/s" SSM
 SG_ RollRate1Qf1 : 43|2@0+ (1,0) [0|3] "" SSM
 SG_ YawRate1 : 23|16@0- (0.000244140625,0.0) [-6.0|6.0] "rad/s" SSM
 SG_ YawRate1Qf1 : 41|2@0+ (1,0) [0|3] "" SSM

BO_ 73 VCU1Mid3CanFr09 : 8 VCU1
 SG_ AdSteerPaddlPsdGroupSafe_UB : 40|1@0+ (1,0) [0|1] "" VIM,VIMB
 SG_ AdSteerPaddlPsdGroupSafeChks : 63|8@0+ (1.0,0.0) [0.0|255.0] "Unitless" VIM,VIMB
 SG_ AdSteerPaddlPsdGroupSafeCntr : 51|4@0+ (1.0,0.0) [0.0|15.0] "Unitless" VIM,VIMB
 SG_ AdSteerPaddlPsdGroupSafeLe : 55|1@0+ (1,0) [0|1] "" VIM,VIMB
 SG_ AdSteerPaddlPsdGroupSafeLeSts : 54|1@0+ (1,0) [0|1] "" VIM,VIMB
 SG_ AdSteerPaddlPsdGroupSafeRi : 53|1@0+ (1,0) [0|1] "" VIM,VIMB
 SG_ AdSteerPaddlPsdGroupSafeRiSts : 52|1@0+ (1,0) [0|1] "" VIM,VIMB
 SG_ SteerWhlAgSafe : 6|15@0- (0.0009765625,0.0) [-14.5|14.5] "rad" SSM,VIM,VIMB
 SG_ SteerWhlAgSpdSafe : 21|14@0- (0.0078125,0.0) [-50.0|50.0] "rad/s" SSM,VIM,VIMB
 SG_ SteerWhlSnsr_UB : 7|1@0+ (1,0) [0|1] "" SSM,VIM,VIMB
 SG_ SteerWhlSnsrQf : 23|2@0+ (1,0) [0|3] "" SSM,VIM,VIMB
 SG_ SteerWhlSnsrSafeChks : 39|8@0+ (1.0,0.0) [0.0|255.0] "Unitless" SSM,VIM,VIMB
 SG_ SteerWhlSnsrSafeCntr : 47|4@0+ (1.0,0.0) [0.0|15.0] "Unitless" SSM,VIM,VIMB
 SG_ WhlMotSysCluSts : 41|1@0+ (1,0) [0|1] "" SSM
 SG_ WhlMotSysCluSts_UB : 42|1@0+ (1,0) [0|1] "" SSM

BO_ 304 VCU1Mid3CanFr10 : 8 VCU1
 SG_ DoorDrvrPosnStsToAPI_UB : 23|1@0+ (1,0) [0|1] "" VIM,VIMB
 SG_ DoorDrvrPosnStsToAPIDrvrDoorPosnSts : 7|4@0+ (1,0) [0|15] "" VIM,VIMB
 SG_ DoorDrvrPosnStsToAPIDrvrDoorPosnStsChks : 15|8@0+ (1.0,0.0) [0.0|255.0] "Unitless" VIM,VIMB
 SG_ DoorDrvrPosnStsToAPIDrvrDoorPosnStsCntr : 3|4@0+ (1.0,0.0) [0.0|15.0] "Unitless" VIM,VIMB
 SG_ DoorDrvrRePosnStsToAPI_UB : 22|1@0+ (1,0) [0|1] "" VIM,VIMB
 SG_ DoorDrvrRePosnStsToAPIDrvrReDoorPosnSts : 31|4@0+ (1,0) [0|15] "" VIM,VIMB
 SG_ DoorDrvrRePosnStsToAPIDrvrReDoorPosnStsChks : 39|8@0+ (1.0,0.0) [0.0|255.0] "Unitless" VIM,VIMB
 SG_ DoorDrvrRePosnStsToAPIDrvrReDoorPosnStsCntr : 27|4@0+ (1.0,0.0) [0.0|15.0] "Unitless" VIM,VIMB
 SG_ DoorPassPosnStsToAPI_UB : 21|1@0+ (1,0) [0|1] "" VIM,VIMB
 SG_ DoorPassPosnStsToAPIPassDoorPosnSts : 47|4@0+ (1,0) [0|15] "" VIM,VIMB
 SG_ DoorPassPosnStsToAPIPassDoorPosnStsChks : 55|8@0+ (1.0,0.0) [0.0|255.0] "Unitless" VIM,VIMB
 SG_ DoorPassPosnStsToAPIPassDoorPosnStsCntr : 43|4@0+ (1.0,0.0) [0.0|15.0] "Unitless" VIM,VIMB
 SG_ EngCooltIndcnReqForExt : 61|4@0+ (1,0) [0|15] "" VIM,VIMB
 SG_ EngCooltIndcnReqForExt_UB : 62|1@0+ (1,0) [0|1] "" VIM,VIMB
 SG_ WiprLvrStsIf_UB : 63|1@0+ (1,0) [0|1] "" VIM,VIMB
 SG_ WiprLvrStsIfWiprFrntSts : 20|3@0+ (1,0) [0|7] "" VIM,VIMB
 SG_ WiprLvrStsIfWiprReSts : 17|2@0+ (1,0) [0|3] "" VIM,VIMB

BO_ 305 VCU1Mid3CanFr11 : 8 VCU1
 SG_ AhbcIndcnToAPI : 47|2@0+ (1,0) [0|3] "" VIM,VIMB
 SG_ AhbcIndcnToAPI_UB : 39|1@0+ (1,0) [0|1] "" VIM,VIMB
 SG_ BltLockStAtDrvr_UB : 58|1@0+ (1,0) [0|1] "" VIM,VIMB
 SG_ BltLockStAtDrvrForBltLockSt1 : 60|1@0+ (1,0) [0|1] "" VIM,VIMB
 SG_ BltLockStAtDrvrForDevErrSts2 : 59|1@0+ (1,0) [0|1] "" VIM,VIMB
 SG_ BltLockStAtPass_UB : 61|1@0+ (1,0) [0|1] "" VIM,VIMB
 SG_ BltLockStAtPassForBltLockSt1 : 63|1@0+ (1,0) [0|1] "" VIM,VIMB
 SG_ BltLockStAtPassForBltLockSts : 62|1@0+ (1,0) [0|1] "" VIM,VIMB
 SG_ BltLockStAtRowSecLe_UB : 48|1@0+ (1,0) [0|1] "" VIM,VIMB
 SG_ BltLockStAtRowSecLeForBltLockEquid : 51|1@0+ (1,0) [0|1] "" VIM,VIMB
 SG_ BltLockStAtRowSecLeForBltLockSt1 : 50|1@0+ (1,0) [0|1] "" VIM,VIMB
 SG_ BltLockStAtRowSecLeForBltLockSts : 49|1@0+ (1,0) [0|1] "" VIM,VIMB
 SG_ BltLockStAtRowSecRi_UB : 52|1@0+ (1,0) [0|1] "" VIM,VIMB
 SG_ BltLockStAtRowSecRiForBltLockEquid : 55|1@0+ (1,0) [0|1] "" VIM,VIMB
 SG_ BltLockStAtRowSecRiForBltLockSt1 : 54|1@0+ (1,0) [0|1] "" VIM,VIMB
 SG_ BltLockStAtRowSecRiForBltLockSts : 53|1@0+ (1,0) [0|1] "" VIM,VIMB
 SG_ DoorDrvrMovmtFailNotif : 21|6@0+ (1,0) [0|63] "" VIM,VIMB
 SG_ DoorDrvrMovmtFailNotif_UB : 22|1@0+ (1,0) [0|1] "" VIM,VIMB
 SG_ DoorDrvrReMovmtFailNotif : 37|6@0+ (1,0) [0|63] "" VIM,VIMB
 SG_ DoorDrvrReMovmtFailNotif_UB : 31|1@0+ (1,0) [0|1] "" VIM,VIMB
 SG_ DoorPassMovmtFailNotif : 29|6@0+ (1,0) [0|63] "" VIM,VIMB
 SG_ DoorPassMovmtFailNotif_UB : 30|1@0+ (1,0) [0|1] "" VIM,VIMB
 SG_ DoorPassReMovmtFailNotif : 45|6@0+ (1,0) [0|63] "" VIM,VIMB
 SG_ DoorPassReMovmtFailNotif_UB : 38|1@0+ (1,0) [0|1] "" VIM,VIMB
 SG_ DoorPassRePosnStsToAPI_UB : 23|1@0+ (1,0) [0|1] "" VIM,VIMB
 SG_ DoorPassRePosnStsToAPIPassReDoorPosnSts : 7|4@0+ (1,0) [0|15] "" VIM,VIMB
 SG_ DoorPassRePosnStsToAPIPassReDoorPosnStsChks : 15|8@0+ (1.0,0.0) [0.0|255.0] "Unitless" VIM,VIMB
 SG_ DoorPassRePosnStsToAPIPassReDoorPosnStsCntr : 3|4@0+ (1.0,0.0) [0.0|15.0] "Unitless" VIM,VIMB

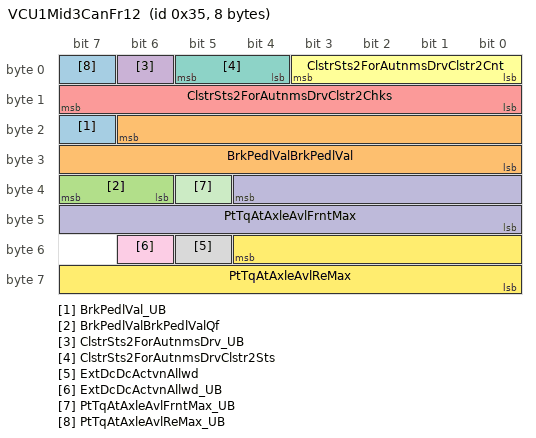
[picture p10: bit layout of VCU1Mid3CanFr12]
BO_ 53 VCU1Mid3CanFr12 : 8 VCU1
 SG_ BrkPedlVal_UB : 23|1@0+ (1,0) [0|1] "" VIM,VIMB
 SG_ BrkPedlValBrkPedlVal : 22|15@0+ (0.00390625,0.0) [0.0|100.0] "%" VIM,VIMB
 SG_ BrkPedlValBrkPedlValQf : 39|2@0+ (1,0) [0|3] "" VIM,VIMB
 SG_ ClstrSts2ForAutnmsDrv_UB : 6|1@0+ (1,0) [0|1] "" SSM,VIM,VIMB
 SG_ ClstrSts2ForAutnmsDrvClstr2Chks : 15|8@0+ (1.0,0.0) [0.0|255.0] "Unitless" SSM,VIM,VIMB
 SG_ ClstrSts2ForAutnmsDrvClstr2Cnt : 3|4@0+ (1.0,0.0) [0.0|15.0] "Unitless" SSM,VIM,VIMB
 SG_ ClstrSts2ForAutnmsDrvClstr2Sts : 5|2@0+ (1,0) [0|3] "" SSM,VIM,VIMB
 SG_ ExtDcDcActvnAllwd : 53|1@0+ (1,0) [0|1] "" VIM,VIMB
 SG_ ExtDcDcActvnAllwd_UB : 54|1@0+ (1,0) [0|1] "" VIM,VIMB
 SG_ PtTqAtAxleAvlFrntMax : 36|13@0- (4.0,0.0) [-16384.0|16380.0] "NewtonMeter" VIM,VIMB
 SG_ PtTqAtAxleAvlFrntMax_UB : 37|1@0+ (1,0) [0|1] "" VIM,VIMB
 SG_ PtTqAtAxleAvlReMax : 52|13@0- (4.0,0.0) [-16384.0|16380.0] "NewtonMeter" VIM,VIMB
 SG_ PtTqAtAxleAvlReMax_UB : 7|1@0+ (1,0) [0|1] "" VIM,VIMB

BO_ 277 VCU1Mid3CanFr13 : 8 VCU1
 SG_ AdActvnOkFromVehDyn : 5|1@0+ (1,0) [0|1] "" SSM,VIM,VIMB
 SG_ AdActvnOkFromVehDyn_UB : 6|1@0+ (1,0) [0|1] "" SSM,VIM,VIMB
 SG_ AutnmsDrvModMngtGlbSafe1_UB : 2|1@0+ (1,0) [0|1] "" SSM
 SG_ AutnmsDrvModMngtGlbSafe1AutnmsDrvModSts1 : 1|2@0+ (1,0) [0|3] "" SSM
 SG_ AutnmsDrvModMngtGlbSafe1AutnmsLowSpdModSts1 : 15|2@0+ (1,0) [0|3] "" SSM
 SG_ AutnmsDrvModMngtGlbSafe1Checksum : 23|8@0+ (1.0,0.0) [0.0|255.0] "Unitless" SSM
 SG_ AutnmsDrvModMngtGlbSafe1Counter : 13|4@0+ (1.0,0.0) [0.0|15.0] "Unitless" SSM
 SG_ AutnmsDrvModMngtGlbSafe1VehOperModSts1 : 9|2@0+ (1,0) [0|3] "" SSM
 SG_ EngFltIndcn_UB : 3|1@0+ (1,0) [0|1] "" VIM,VIMB
 SG_ EngFltIndcnEngFltIndcn1 : 31|1@0+ (1,0) [0|1] "" VIM,VIMB
 SG_ EngFltIndcnEngFltIndcn10 : 38|1@0+ (1,0) [0|1] "" VIM,VIMB
 SG_ EngFltIndcnEngFltIndcn11 : 37|1@0+ (1,0) [0|1] "" VIM,VIMB
 SG_ EngFltIndcnEngFltIndcn12 : 36|1@0+ (1,0) [0|1] "" VIM,VIMB
 SG_ EngFltIndcnEngFltIndcn13 : 35|1@0+ (1,0) [0|1] "" VIM,VIMB
 SG_ EngFltIndcnEngFltIndcn14 : 34|1@0+ (1,0) [0|1] "" VIM,VIMB
 SG_ EngFltIndcnEngFltIndcn15 : 33|1@0+ (1,0) [0|1] "" VIM,VIMB
 SG_ EngFltIndcnEngFltIndcn16 : 32|1@0+ (1,0) [0|1] "" VIM,VIMB
 SG_ EngFltIndcnEngFltIndcn17 : 47|1@0+ (1,0) [0|1] "" VIM,VIMB
 SG_ EngFltIndcnEngFltIndcn18 : 46|1@0+ (1,0) [0|1] "" VIM,VIMB
 SG_ EngFltIndcnEngFltIndcn19 : 45|1@0+ (1,0) [0|1] "" VIM,VIMB
 SG_ EngFltIndcnEngFltIndcn2 : 30|1@0+ (1,0) [0|1] "" VIM,VIMB
 SG_ EngFltIndcnEngFltIndcn20 : 44|1@0+ (1,0) [0|1] "" VIM,VIMB
 SG_ EngFltIndcnEngFltIndcn21 : 43|1@0+ (1,0) [0|1] "" VIM,VIMB
 SG_ EngFltIndcnEngFltIndcn22 : 42|1@0+ (1,0) [0|1] "" VIM,VIMB
 SG_ EngFltIndcnEngFltIndcn23 : 41|1@0+ (1,0) [0|1] "" VIM,VIMB
 SG_ EngFltIndcnEngFltIndcn24 : 40|1@0+ (1,0) [0|1] "" VIM,VIMB
 SG_ EngFltIndcnEngFltIndcn25 : 55|1@0+ (1,0) [0|1] "" VIM,VIMB
 SG_ EngFltIndcnEngFltIndcn26 : 54|1@0+ (1,0) [0|1] "" VIM,VIMB
 SG_ EngFltIndcnEngFltIndcn27 : 53|1@0+ (1,0) [0|1] "" VIM,VIMB
 SG_ EngFltIndcnEngFltIndcn3 : 29|1@0+ (1,0) [0|1] "" VIM,VIMB
 SG_ EngFltIndcnEngFltIndcn4 : 28|1@0+ (1,0) [0|1] "" VIM,VIMB
 SG_ EngFltIndcnEngFltIndcn5 : 27|1@0+ (1,0) [0|1] "" VIM,VIMB
 SG_ EngFltIndcnEngFltIndcn6 : 26|1@0+ (1,0) [0|1] "" VIM,VIMB
 SG_ EngFltIndcnEngFltIndcn7 : 25|1@0+ (1,0) [0|1] "" VIM,VIMB
 SG_ EngFltIndcnEngFltIndcn8 : 24|1@0+ (1,0) [0|1] "" VIM,VIMB
 SG_ EngFltIndcnEngFltIndcn9 : 39|1@0+ (1,0) [0|1] "" VIM,VIMB
 SG_ PtTqAtAxleAvlReMaxLong : 52|13@0- (4.0,0.0) [-16384.0|16380.0] "NewtonMeter" VIM,VIMB
 SG_ PtTqAtAxleAvlReMaxLong_UB : 4|1@0+ (1,0) [0|1] "" VIM,VIMB

// Node Comments
CM_ BU_ ETC "External Tester Connector";
CM_ BU_ VCU1 "Vehicle Computational Unit 1";

// Signal Comments
CM_ SG_ 1408 VCU1DevReceiveMid3Fr1Byte0 " Byte0";
CM_ SG_ 1408 VCU1DevReceiveMid3Fr1Byte1 " Byte1";
CM_ SG_ 1408 VCU1DevReceiveMid3Fr1Byte2 " Byte2";
CM_ SG_ 1408 VCU1DevReceiveMid3Fr1Byte3 " Byte3";
CM_ SG_ 1408 VCU1DevReceiveMid3Fr1Byte4 " Byte4";
CM_ SG_ 1408 VCU1DevReceiveMid3Fr1Byte5 " Byte5";
CM_ SG_ 1408 VCU1DevReceiveMid3Fr1Byte6 " Byte6";
CM_ SG_ 1408 VCU1DevReceiveMid3Fr1Byte7 " Byte7";
CM_ SG_ 1409 VCU1DevReceiveMid3Fr2Byte0 " Byte0";
CM_ SG_ 1409 VCU1DevReceiveMid3Fr2Byte1 " Byte1";
CM_ SG_ 1409 VCU1DevReceiveMid3Fr2Byte2 " Byte2";
CM_ SG_ 1409 VCU1DevReceiveMid3Fr2Byte3 " Byte3";
CM_ SG_ 1409 VCU1DevReceiveMid3Fr2Byte4 " Byte4";
CM_ SG_ 1409 VCU1DevReceiveMid3Fr2Byte5 " Byte5";
CM_ SG_ 1409 VCU1DevReceiveMid3Fr2Byte6 " Byte6";
CM_ SG_ 1409 VCU1DevReceiveMid3Fr2Byte7 " Byte7";
CM_ SG_ 1410 VCU1DevReceiveMid3Fr3Byte0 " Byte0";
CM_ SG_ 1410 VCU1DevReceiveMid3Fr3Byte1 " Byte1";
CM_ SG_ 1410 VCU1DevReceiveMid3Fr3Byte2 " Byte2";
CM_ SG_ 1410 VCU1DevReceiveMid3Fr3Byte3 " Byte3";
CM_ SG_ 1410 VCU1DevReceiveMid3Fr3Byte4 " Byte4";
CM_ SG_ 1410 VCU1DevReceiveMid3Fr3Byte5 " Byte5";
CM_ SG_ 1410 VCU1DevReceiveMid3Fr3Byte6 " Byte6";
CM_ SG_ 1410 VCU1DevReceiveMid3Fr3Byte7 " Byte7";
CM_ SG_ 1411 VCU1DevReceiveMid3Fr4Byte0 " Byte0";
CM_ SG_ 1411 VCU1DevReceiveMid3Fr4Byte1 " Byte1";
CM_ SG_ 1411 VCU1DevReceiveMid3Fr4Byte2 " Byte2";
CM_ SG_ 1411 VCU1DevReceiveMid3Fr4Byte3 " Byte3";
CM_ SG_ 1411 VCU1DevReceiveMid3Fr4Byte4 " Byte4";
CM_ SG_ 1411 VCU1DevReceiveMid3Fr4Byte5 " Byte5";
CM_ SG_ 1411 VCU1DevReceiveMid3Fr4Byte6 " Byte6";
CM_ SG_ 1411 VCU1DevReceiveMid3Fr4Byte7 " Byte7";
CM_ SG_ 1412 VCU1DevReceiveMid3Fr5Byte0 " Byte0";
CM_ SG_ 1412 VCU1DevReceiveMid3Fr5Byte1 " Byte1";
CM_ SG_ 1412 VCU1DevReceiveMid3Fr5Byte2 " Byte2";
CM_ SG_ 1412 VCU1DevReceiveMid3Fr5Byte3 " Byte3";
CM_ SG_ 1412 VCU1DevReceiveMid3Fr5Byte4 " Byte4";
CM_ SG_ 1412 VCU1DevReceiveMid3Fr5Byte5 " Byte5";
CM_ SG_ 1412 VCU1DevReceiveMid3Fr5Byte6 " Byte6";
CM_ SG_ 1412 VCU1DevReceiveMid3Fr5Byte7 " Byte7";
CM_ SG_ 262 AdSecSteerModStsSafeGroupByGatewyAdSteerMod " AD mode perceived by Steering System";
CM_ SG_ 262 AdSecSteerModStsSafeGroupByGatewyChks " E2E-protection";
CM_ SG_ 262 AdSecSteerModStsSafeGroupByGatewyCntr " E2E-protection";
CM_ SG_ 262 AdSecSteerModStsSafeGroupByGatewyVehOperIntv " Vehicle Operator intervention detected by Steering System";
CM_ SG_ 262 AdSecSteerModStsSafeGroupByGatewyVehOperModSts1 " Vehicle Operator status perceived by Steering System";
CM_ SG_ 262 AdSecSteerStsSafeGroupByGatewyAdSteerPerf "This signal group contains information from the steering system.
In specifics, the overall performance of the steering system, based on current, voltage, heat and degradation.

This is done by a level of abstraction:

AdSteerSts: 
DegradedLvl4 = No device available for AD operations
DegradedLvl3 = Degradation is present in the only available device
DegradedLvl2 = A single device is available for AD operations
DegradedLvl1 = A degradation is present in of of the two devices. Full availability.
SysOK = Redudant devices available. No degradation.

AdSteerPerf: 
A scale from 0-100% of motor performance that can be given by the steering system.
Measured by current, voltage, heat and the current level of degradation seen in AdSteerSts. Performance of MotorHalf1 + MotorHalf2";
CM_ SG_ 262 AdSecSteerStsSafeGroupByGatewyAdSteerSts "This signal group contains information from the steering system.
In specifics, the overall performance of the steering system, based on current, voltage, heat and degradation.

This is done by a level of abstraction:

AdSteerSts: 
DegradedLvl4 = No device available for AD operations
DegradedLvl3 = Degradation is present in the only available device
DegradedLvl2 = A single device is available for AD operations
DegradedLvl1 = A degradation is present in of of the two devices. Full availability.
SysOK = Redudant devices available. No degradation.

AdSteerPerf: 
A scale from 0-100% of motor performance that can be given by the steering system.
Measured by current, voltage, heat and the current level of degradation seen in AdSteerSts. Status of steering system";
CM_ SG_ 262 AdSecSteerStsSafeGroupByGatewyChks "This signal group contains information from the steering system.
In specifics, the overall performance of the steering system, based on current, voltage, heat and degradation.

This is done by a level of abstraction:

AdSteerSts: 
DegradedLvl4 = No device available for AD operations
DegradedLvl3 = Degradation is present in the only available device
DegradedLvl2 = A single device is available for AD operations
DegradedLvl1 = A degradation is present in of of the two devices. Full availability.
SysOK = Redudant devices available. No degradation.

AdSteerPerf: 
A scale from 0-100% of motor performance that can be given by the steering system.
Measured by current, voltage, heat and the current level of degradation seen in AdSteerSts. E2E-protection";
CM_ SG_ 262 AdSecSteerStsSafeGroupByGatewyCntr "This signal group contains information from the steering system.
In specifics, the overall performance of the steering system, based on current, voltage, heat and degradation.

This is done by a level of abstraction:

AdSteerSts: 
DegradedLvl4 = No device available for AD operations
DegradedLvl3 = Degradation is present in the only available device
DegradedLvl2 = A single device is available for AD operations
DegradedLvl1 = A degradation is present in of of the two devices. Full availability.
SysOK = Redudant devices available. No degradation.

AdSteerPerf: 
A scale from 0-100% of motor performance that can be given by the steering system.
Measured by current, voltage, heat and the current level of degradation seen in AdSteerSts. E2E-protection";
CM_ SG_ 55 PrimSafeStopActv1Chks " E2E checksum";
CM_ SG_ 55 PrimSafeStopActv1Cntr " E2E counter";
CM_ SG_ 55 PrimSafeStopActv1PlatformSafeStopActv " Safe stop active";
CM_ SG_ 99 PrimVehSpdGroupSafeChks "Vehicle speed over ground and Moving direction (Primary) Checksum";
CM_ SG_ 99 PrimVehSpdGroupSafeCntr "Vehicle speed over ground and Moving direction (Primary) Counter";
CM_ SG_ 99 PrimVehSpdGroupSafeMax "Vehicle speed over ground and Moving direction (Primary) Maximum vehicle speed over ground";
CM_ SG_ 99 PrimVehSpdGroupSafeMin "Vehicle speed over ground and Moving direction (Primary) Minimum vehicle speed over ground";
CM_ SG_ 99 PrimVehSpdGroupSafeMinMaxQf "Vehicle speed over ground and Moving direction (Primary) Quality factor for Min and Max signals";
CM_ SG_ 99 PrimVehSpdGroupSafeMovDir "Vehicle speed over ground and Moving direction (Primary) Actual moving direction";
CM_ SG_ 99 PrimVehSpdGroupSafeMovDirQf "Vehicle speed over ground and Moving direction (Primary) Quality factor for Actual moving direction";
CM_ SG_ 99 PrimVehSpdGroupSafeNom "Vehicle speed over ground and Moving direction (Primary) Nominal vehicle speed over ground";
CM_ SG_ 99 PrimVehSpdGroupSafeNomQf "Vehicle speed over ground and Moving direction (Primary) Quality factor for Nom signal";
CM_ SG_ 52 PrimALgtDataRawSafeChks "Longitudinal acceleration estimation (Primary) Checksum";
CM_ SG_ 52 PrimALgtDataRawSafeCntr "Longitudinal acceleration estimation (Primary) Counter";
CM_ SG_ 52 PrimALgtDataRawSafeMax "Longitudinal acceleration estimation (Primary) Maximum longitudinal acceleration";
CM_ SG_ 52 PrimALgtDataRawSafeMin "Longitudinal acceleration estimation (Primary) Minimum longitudinal acceleration";
CM_ SG_ 52 PrimALgtDataRawSafeMinMaxQf "Longitudinal acceleration estimation (Primary) Quality factor for Min and Max signals";
CM_ SG_ 52 PrimALgtDataRawSafeNom "Longitudinal acceleration estimation (Primary) Nominal longitudinal acceleration";
CM_ SG_ 52 PrimALgtDataRawSafeNomQf "Longitudinal acceleration estimation (Primary) Quality factor for Nom signal";
CM_ SG_ 1413 VCU1DevSendMid3Fr1Byte0 " Byte0";
CM_ SG_ 1413 VCU1DevSendMid3Fr1Byte1 " Byte1";
CM_ SG_ 1413 VCU1DevSendMid3Fr1Byte2 " Byte2";
CM_ SG_ 1413 VCU1DevSendMid3Fr1Byte3 " Byte3";
CM_ SG_ 1413 VCU1DevSendMid3Fr1Byte4 " Byte4";
CM_ SG_ 1413 VCU1DevSendMid3Fr1Byte5 " Byte5";
CM_ SG_ 1413 VCU1DevSendMid3Fr1Byte6 " Byte6";
CM_ SG_ 1413 VCU1DevSendMid3Fr1Byte7 " Byte7";
CM_ SG_ 1414 VCU1DevSendMid3Fr2Byte0 " Byte0";
CM_ SG_ 1414 VCU1DevSendMid3Fr2Byte1 " Byte1";
CM_ SG_ 1414 VCU1DevSendMid3Fr2Byte2 " Byte2";
CM_ SG_ 1414 VCU1DevSendMid3Fr2Byte3 " Byte3";
CM_ SG_ 1414 VCU1DevSendMid3Fr2Byte4 " Byte4";
CM_ SG_ 1414 VCU1DevSendMid3Fr2Byte5 " Byte5";
CM_ SG_ 1414 VCU1DevSendMid3Fr2Byte6 " Byte6";
CM_ SG_ 1414 VCU1DevSendMid3Fr2Byte7 " Byte7";
CM_ SG_ 1415 VCU1DevSendMid3Fr3Byte0 " Byte0";
CM_ SG_ 1415 VCU1DevSendMid3Fr3Byte1 " Byte1";
CM_ SG_ 1415 VCU1DevSendMid3Fr3Byte2 " Byte2";
CM_ SG_ 1415 VCU1DevSendMid3Fr3Byte3 " Byte3";
CM_ SG_ 1415 VCU1DevSendMid3Fr3Byte4 " Byte4";
CM_ SG_ 1415 VCU1DevSendMid3Fr3Byte5 " Byte5";
CM_ SG_ 1415 VCU1DevSendMid3Fr3Byte6 " Byte6";
CM_ SG_ 1415 VCU1DevSendMid3Fr3Byte7 " Byte7";
CM_ SG_ 1416 VCU1DevSendMid3Fr4Byte0 " Byte0";
CM_ SG_ 1416 VCU1DevSendMid3Fr4Byte1 " Byte1";
CM_ SG_ 1416 VCU1DevSendMid3Fr4Byte2 " Byte2";
CM_ SG_ 1416 VCU1DevSendMid3Fr4Byte3 " Byte3";
CM_ SG_ 1416 VCU1DevSendMid3Fr4Byte4 " Byte4";
CM_ SG_ 1416 VCU1DevSendMid3Fr4Byte5 " Byte5";
CM_ SG_ 1416 VCU1DevSendMid3Fr4Byte6 " Byte6";
CM_ SG_ 1416 VCU1DevSendMid3Fr4Byte7 " Byte7";
CM_ SG_ 1417 VCU1DevSendMid3Fr5Byte0 " Byte0";
CM_ SG_ 1417 VCU1DevSendMid3Fr5Byte1 " Byte1";
CM_ SG_ 1417 VCU1DevSendMid3Fr5Byte2 " Byte2";
CM_ SG_ 1417 VCU1DevSendMid3Fr5Byte3 " Byte3";
CM_ SG_ 1417 VCU1DevSendMid3Fr5Byte4 " Byte4";
CM_ SG_ 1417 VCU1DevSendMid3Fr5Byte5 " Byte5";
CM_ SG_ 1417 VCU1DevSendMid3Fr5Byte6 " Byte6";
CM_ SG_ 1417 VCU1DevSendMid3Fr5Byte7 " Byte7";
CM_ SG_ 48 AdPrimSteerStsSafeGroupAdSteerPerf " Performance of MotorHalf1 + MotorHalf2";
CM_ SG_ 48 AdPrimSteerStsSafeGroupAdSteerSts " Status of steering system";
CM_ SG_ 48 AdPrimSteerStsSafeGroupChks " E2E-protection";
CM_ SG_ 48 AdPrimSteerStsSafeGroupCntr " E2E-protection";
CM_ SG_ 48 CarModInCrashStsSafeChks "Indicates if CarModSts==Crash is TRUE or FALSE with E2E protection. End to end checksum";
CM_ SG_ 48 CarModInCrashStsSafeCntr "Indicates if CarModSts==Crash is TRUE or FALSE with E2E protection. End to End Counter";
CM_ SG_ 48 CarModInCrashStsSafeSts "Indicates if CarModSts==Crash is TRUE or FALSE with E2E protection. Car Mode Crash status";
CM_ SG_ 64 BrkTqMinReqBrkActrCtrlModForMinTqReq "Vehicle brake torque request for autonomous driving Brake actuator mode for brake torque actuation";
CM_ SG_ 64 BrkTqMinReqBrkTqGrdtNegMinReq "Vehicle brake torque request for autonomous driving Allowed negative brake torque gradient";
CM_ SG_ 64 BrkTqMinReqBrkTqGrdtPosMinReq "Vehicle brake torque request for autonomous driving Allowed positive brake torque gradient";
CM_ SG_ 64 BrkTqMinReqBrkTqMinReq "Vehicle brake torque request for autonomous driving Minimum vehicle brake torque request";
CM_ SG_ 64 BrkTqMinReqBrkTqMinReqChks "Vehicle brake torque request for autonomous driving Checksum";
CM_ SG_ 64 BrkTqMinReqBrkTqMinReqCntr "Vehicle brake torque request for autonomous driving Counter";
CM_ SG_ 64 HornActvIf "Information whether the horn actuator is activated or not.

1 = Off
2 = On";
CM_ SG_ 64 HornSwtStsIf "Information about the status of the horn switch, triggered/not triggered.

1 = Off
2 = On";
CM_ SG_ 64 WshrFldLvlContnsIf "Used to inform about the fluid level status in the additional tank used by the sensor cleaning system.

0 = Initial value (not used)
1 = Lowest value (empty reservoir)
31 = Highest value (full reservoir)";
CM_ SG_ 85 AdSecSteerActvnGroupSafeAdSteerActvnReq "AdSteerActvnReq
Dimension: 1
Initial value: Off
Description
attribute:
Request to activate steering system autonomous drive functionality.
Value Identifier Description
0 Off Off
1 On On

AdSteerDeActvnReq
Dimension: 1
Initial value: Off
Description
attribute:
Request to deactivate steering system autonomous drive functionality.
Value Identifier Description
0 Off Off
1 On On Request to activate steering system autonomous drive functionality.";
CM_ SG_ 85 AdSecSteerActvnGroupSafeAdSteerDeActvnReq "AdSteerActvnReq
Dimension: 1
Initial value: Off
Description
attribute:
Request to activate steering system autonomous drive functionality.
Value Identifier Description
0 Off Off
1 On On

AdSteerDeActvnReq
Dimension: 1
Initial value: Off
Description
attribute:
Request to deactivate steering system autonomous drive functionality.
Value Identifier Description
0 Off Off
1 On On Request to deactivate steering system autonomous drive functionality.";
CM_ SG_ 85 AdSecSteerActvnGroupSafeChks "AdSteerActvnReq
Dimension: 1
Initial value: Off
Description
attribute:
Request to activate steering system autonomous drive functionality.
Value Identifier Description
0 Off Off
1 On On

AdSteerDeActvnReq
Dimension: 1
Initial value: Off
Description
attribute:
Request to deactivate steering system autonomous drive functionality.
Value Identifier Description
0 Off Off
1 On On E2E-protection";
CM_ SG_ 85 AdSecSteerActvnGroupSafeCntr "AdSteerActvnReq
Dimension: 1
Initial value: Off
Description
attribute:
Request to activate steering system autonomous drive functionality.
Value Identifier Description
0 Off Off
1 On On

AdSteerDeActvnReq
Dimension: 1
Initial value: Off
Description
attribute:
Request to deactivate steering system autonomous drive functionality.
Value Identifier Description
0 Off Off
1 On On E2E-protection";
CM_ SG_ 85 PrpsnTqDirAct " Propulsion torque actual direction";
CM_ SG_ 85 PrpsnTqDirChks " Checksum";
CM_ SG_ 85 PrpsnTqDirCntr " Counter";
CM_ SG_ 85 SteerWhlTq "Torque on steering wheel Torque on steering wheel";
CM_ SG_ 85 SteerWhlTqQf "Torque on steering wheel Quality factor for SteerWhlTq";
CM_ SG_ 98 FricEstimnFromVehDyn "Momentary friction estimate Momentary friction estimate.";
CM_ SG_ 98 FricEstimnFromVehDynQly "Momentary friction estimate Quality of momentary friction estimate.";
CM_ SG_ 98 PrpsnTqDirCpbyChks "Propulsion torque direction capability Checksum";
CM_ SG_ 98 PrpsnTqDirCpbyCntr "Propulsion torque direction capability Counter";
CM_ SG_ 98 PrpsnTqDirCpbySts "Propulsion torque direction capability Propulsion torque capability";
CM_ SG_ 98 SwtExtrLiToAPILiExtFctCntr "This signal shows the status of the physical Light Switch Module (LSM) position. Counter";
CM_ SG_ 98 SwtExtrLiToAPILiExtFctCrc "This signal shows the status of the physical Light Switch Module (LSM) position. J1850 CRC";
CM_ SG_ 98 SwtExtrLiToAPILiExtFctQf "This signal shows the status of the physical Light Switch Module (LSM) position. Quality factor";
CM_ SG_ 98 SwtExtrLiToAPILiExtFctReq1 "This signal shows the status of the physical Light Switch Module (LSM) position. Data";
CM_ SG_ 153 AdSecBlindStopMonActvnGroupSafeActvnReq "<17w21.3 mnordstr>: Request from LAC LongControlSafe (SSM) to LAC LongControlSafeRdnt (SSMB) to enter AD Mode. Added without explicit FR-requirements, since those are only mentioning SSM. Communication between SSM and SSMB needs to be defined. This DATA-ELEM handles the request to activate. Request to activate AD-mode in 'SSM' from 'VCU1'.";
CM_ SG_ 153 AdSecBlindStopMonActvnGroupSafeChks "<17w21.3 mnordstr>: Request from LAC LongControlSafe (SSM) to LAC LongControlSafeRdnt (SSMB) to enter AD Mode. Added without explicit FR-requirements, since those are only mentioning SSM. Communication between SSM and SSMB needs to be defined. This DATA-ELEM handles the request to activate.";
CM_ SG_ 153 AdSecBlindStopMonActvnGroupSafeCntr "<17w21.3 mnordstr>: Request from LAC LongControlSafe (SSM) to LAC LongControlSafeRdnt (SSMB) to enter AD Mode. Added without explicit FR-requirements, since those are only mentioning SSM. Communication between SSM and SSMB needs to be defined. This DATA-ELEM handles the request to activate.";
CM_ SG_ 153 AdSecBlindStopMonActvnGroupSafeDeactvnReq "<17w21.3 mnordstr>: Request from LAC LongControlSafe (SSM) to LAC LongControlSafeRdnt (SSMB) to enter AD Mode. Added without explicit FR-requirements, since those are only mentioning SSM. Communication between SSM and SSMB needs to be defined. This DATA-ELEM handles the request to activate. Request to deactivate AD-mode in 'SSM' from 'VCU1'.";
CM_ SG_ 153 DrvrGearShiftManReqDwnTipReq "Driver tip request from gear shifter or steering wheel for gear selection. Valid for Shift-By-Wire system. Tip down request";
CM_ SG_ 153 DrvrGearShiftManReqSteerWhlDwnReq "Driver tip request from gear shifter or steering wheel for gear selection. Valid for Shift-By-Wire system. Paddle down request";
CM_ SG_ 153 DrvrGearShiftManReqSteerWhlUpReq "Driver tip request from gear shifter or steering wheel for gear selection. Valid for Shift-By-Wire system. Paddle up request";
CM_ SG_ 153 DrvrGearShiftManReqTipReq "Driver tip request from gear shifter or steering wheel for gear selection. Valid for Shift-By-Wire system. Tip request";
CM_ SG_ 153 DrvrGearShiftManReqUpTipReq "Driver tip request from gear shifter or steering wheel for gear selection. Valid for Shift-By-Wire system. Tip up request";
CM_ SG_ 153 PassSeatSts "Occupation status of the front passenger seat.";
CM_ SG_ 153 SnsrClngErrIfActr1 "Distributes information regarding a failure related to the sensor cleaning system.
Signals are of type Fault/No Fault.

SysClngFailr = Cleaning system general failure
Actr1 = Failure related to cleaning actuator #1
Actr2 = Failure related to cleaning actuator #2
Actr3 = Failure related to cleaning actuator #3
WshrFldSnsrFailr = Failure related to the continuous washer fluid level sensor used by the sensor cleaning system.


 Actuator 1 failure";
CM_ SG_ 153 SnsrClngErrIfActr2 "Distributes information regarding a failure related to the sensor cleaning system.
Signals are of type Fault/No Fault.

SysClngFailr = Cleaning system general failure
Actr1 = Failure related to cleaning actuator #1
Actr2 = Failure related to cleaning actuator #2
Actr3 = Failure related to cleaning actuator #3
WshrFldSnsrFailr = Failure related to the continuous washer fluid level sensor used by the sensor cleaning system.


 Actuator 2 failure";
CM_ SG_ 153 SnsrClngErrIfActr3 "Distributes information regarding a failure related to the sensor cleaning system.
Signals are of type Fault/No Fault.

SysClngFailr = Cleaning system general failure
Actr1 = Failure related to cleaning actuator #1
Actr2 = Failure related to cleaning actuator #2
Actr3 = Failure related to cleaning actuator #3
WshrFldSnsrFailr = Failure related to the continuous washer fluid level sensor used by the sensor cleaning system.


 Actuator 3 failure";
CM_ SG_ 153 SnsrClngErrIfRsvd1 "Distributes information regarding a failure related to the sensor cleaning system.
Signals are of type Fault/No Fault.

SysClngFailr = Cleaning system general failure
Actr1 = Failure related to cleaning actuator #1
Actr2 = Failure related to cleaning actuator #2
Actr3 = Failure related to cleaning actuator #3
WshrFldSnsrFailr = Failure related to the continuous washer fluid level sensor used by the sensor cleaning system.


";
CM_ SG_ 153 SnsrClngErrIfRsvd2 "Distributes information regarding a failure related to the sensor cleaning system.
Signals are of type Fault/No Fault.

SysClngFailr = Cleaning system general failure
Actr1 = Failure related to cleaning actuator #1
Actr2 = Failure related to cleaning actuator #2
Actr3 = Failure related to cleaning actuator #3
WshrFldSnsrFailr = Failure related to the continuous washer fluid level sensor used by the sensor cleaning system.


";
CM_ SG_ 153 SnsrClngErrIfRsvd3 "Distributes information regarding a failure related to the sensor cleaning system.
Signals are of type Fault/No Fault.

SysClngFailr = Cleaning system general failure
Actr1 = Failure related to cleaning actuator #1
Actr2 = Failure related to cleaning actuator #2
Actr3 = Failure related to cleaning actuator #3
WshrFldSnsrFailr = Failure related to the continuous washer fluid level sensor used by the sensor cleaning system.


";
CM_ SG_ 153 SnsrClngErrIfSysClngFailr "Distributes information regarding a failure related to the sensor cleaning system.
Signals are of type Fault/No Fault.

SysClngFailr = Cleaning system general failure
Actr1 = Failure related to cleaning actuator #1
Actr2 = Failure related to cleaning actuator #2
Actr3 = Failure related to cleaning actuator #3
WshrFldSnsrFailr = Failure related to the continuous washer fluid level sensor used by the sensor cleaning system.


 Cleaning system failure";
CM_ SG_ 153 SnsrClngErrIfWshrFldSnsrFailr "Distributes information regarding a failure related to the sensor cleaning system.
Signals are of type Fault/No Fault.

SysClngFailr = Cleaning system general failure
Actr1 = Failure related to cleaning actuator #1
Actr2 = Failure related to cleaning actuator #2
Actr3 = Failure related to cleaning actuator #3
WshrFldSnsrFailr = Failure related to the continuous washer fluid level sensor used by the sensor cleaning system.


 Washer fluid sensor failure";
CM_ SG_ 153 VehM "Estimated vehicle mass including trailer. Vehicle mass including trailer mass (if connected).";
CM_ SG_ 153 VehMNomTrlrM "Estimated vehicle mass including trailer. Estimated trailer mass";
CM_ SG_ 153 VehMQly "Estimated vehicle mass including trailer. Quality for vehicle mass information";
CM_ SG_ 153 WinWipgAutCmdIf "Distributes information about wiping speed (in RPM) commanded by the rain sensor in case automatic wiping is activated.";
CM_ SG_ 153 WipgFrntAutModIf "Wiping mode commanded by the rain sensor in case automatic wiping is activated.

WipgAutFrntMod0 = 0,	// Off
WipgAutFrntMod1 = 1,	// Direct Mode
WipgAutFrntMod2 = 2,	// Interval Mode
WipgAutFrntMod3 = 3	// Continous Mode";
CM_ SG_ 153 WiprActvIf "Information about whether the front wiper is active/not active:

0 = Off
1 = On";
CM_ SG_ 153 WshngCycActvIf "Information regarding the state of front windscreen washing

0 = Front windscreen washing cycle not active
1 = Front windscreen washing cycle active";
CM_ SG_ 896 CarTiGlb "Presents a tiime value that shall be used by all ECUs to time-stamp diagnsotic trouble codes (DTC) according to the requirements for Global DTC snapshot data.";
CM_ SG_ 57 AgDataRawSafeChks "IMU angular rate data. Check summa";
CM_ SG_ 57 AgDataRawSafeCntr "IMU angular rate data. Counter";
CM_ SG_ 57 ClstrSts1ForAutnmsDrvClstr1Chks "Cluster1 Status.  Checksum";
CM_ SG_ 57 ClstrSts1ForAutnmsDrvClstr1Cnt "Cluster1 Status.  Counter";
CM_ SG_ 57 ClstrSts1ForAutnmsDrvClstr1Sts "Cluster1 Status.  LV Cluster 1 Status";
CM_ SG_ 57 RollRate1 "IMU angular rate data. Roll Rate";
CM_ SG_ 57 RollRate1Qf1 "IMU angular rate data. Quality factor for Roll Rate";
CM_ SG_ 57 YawRate1 "IMU angular rate data. Yaw Rate";
CM_ SG_ 57 YawRate1Qf1 "IMU angular rate data. Quality Factor for Yaw Rate";
CM_ SG_ 73 AdSteerPaddlPsdGroupSafeChks " E2E Checksum";
CM_ SG_ 73 AdSteerPaddlPsdGroupSafeCntr " E2E counter";
CM_ SG_ 73 AdSteerPaddlPsdGroupSafeLe " Left paddle pressed";
CM_ SG_ 73 AdSteerPaddlPsdGroupSafeLeSts " Status flag of left paddle";
CM_ SG_ 73 AdSteerPaddlPsdGroupSafeRi " Right paddle pressed";
CM_ SG_ 73 AdSteerPaddlPsdGroupSafeRiSts " Status flag of right paddle";
CM_ SG_ 73 SteerWhlAgSafe "Actual steering wheel angle from the actual centre position of the steering wheel. The signal value is a signed value from zero (at centre steering wheel position) where a left turn (counterclockwise from steering wheel centre position) is represented by positive values and right turn (clockwise from steering wheel centre position) will have negative value.  Actual steering wheel angle from the actual centre position of the steering wheel. The signal value is a signed value from zero (at centre steering wheel position) where a left turn (counterclockwise from steering wheel centre position) is represented by positive values and right turn (clockwise from steering wheel centre position) will have negative value. ";
CM_ SG_ 73 SteerWhlAgSpdSafe "Actual steering wheel angle from the actual centre position of the steering wheel. The signal value is a signed value from zero (at centre steering wheel position) where a left turn (counterclockwise from steering wheel centre position) is represented by positive values and right turn (clockwise from steering wheel centre position) will have negative value.  Steering angle speed with steering wheel rotation direction.  Turning the steering wheel left (counterclockwise) is represented by positive values and turning the steering wheel right (clockwise) is represented by negative values.";
CM_ SG_ 73 SteerWhlSnsrQf "Actual steering wheel angle from the actual centre position of the steering wheel. The signal value is a signed value from zero (at centre steering wheel position) where a left turn (counterclockwise from steering wheel centre position) is represented by positive values and right turn (clockwise from steering wheel centre position) will have negative value.  Qf for steering wheel sensor information";
CM_ SG_ 73 SteerWhlSnsrSafeChks "Actual steering wheel angle from the actual centre position of the steering wheel. The signal value is a signed value from zero (at centre steering wheel position) where a left turn (counterclockwise from steering wheel centre position) is represented by positive values and right turn (clockwise from steering wheel centre position) will have negative value.  Checksum for steering wheel sensor data.";
CM_ SG_ 73 SteerWhlSnsrSafeCntr "Actual steering wheel angle from the actual centre position of the steering wheel. The signal value is a signed value from zero (at centre steering wheel position) where a left turn (counterclockwise from steering wheel centre position) is represented by positive values and right turn (clockwise from steering wheel centre position) will have negative value.  Counter value for steering wheel sensor data.";
CM_ SG_ 73 WhlMotSysCluSts "Desscribing the state of the ERAD clutch. Open or Closed. If state is transitioning between Closed to Open it will report closed until it is verified open. ";
CM_ SG_ 304 DoorDrvrPosnStsToAPIDrvrDoorPosnSts " Position status of the driver door";
CM_ SG_ 304 DoorDrvrPosnStsToAPIDrvrDoorPosnStsChks " Checksum for position status of driver door";
CM_ SG_ 304 DoorDrvrPosnStsToAPIDrvrDoorPosnStsCntr " Counter for position status of driver door";
CM_ SG_ 304 DoorDrvrRePosnStsToAPIDrvrReDoorPosnSts " Position status of the rear driver door";
CM_ SG_ 304 DoorDrvrRePosnStsToAPIDrvrReDoorPosnStsChks " Checksum for position status of rear driver door";
CM_ SG_ 304 DoorDrvrRePosnStsToAPIDrvrReDoorPosnStsCntr " Counter for position status of rear driver door";
CM_ SG_ 304 DoorPassPosnStsToAPIPassDoorPosnSts " Position status of the passenger door";
CM_ SG_ 304 DoorPassPosnStsToAPIPassDoorPosnStsChks " Checksum for position status of passenger door";
CM_ SG_ 304 DoorPassPosnStsToAPIPassDoorPosnStsCntr " Counter for position status of passenger door";
CM_ SG_ 304 EngCooltIndcnReqForExt "Request to display warning / info message to customer in DIM regarding engine cooling system. Possible warning messages:
- no message
- high engine temp reduce speed
- high engine temp stop safely
- high engine temp stop engine
- high engine temp see manual
- coolant low stop engine
- coolant low stop safely
- coolant low see manual
- coolant low check level
- coolant system service required";
CM_ SG_ 304 WiprLvrStsIfWiprFrntSts " Wiper front lever status.";
CM_ SG_ 304 WiprLvrStsIfWiprReSts " Rear wiper button status.";
CM_ SG_ 305 AhbcIndcnToAPI "This signal shows if the AHB system is activated or not.";
CM_ SG_ 305 BltLockStAtDrvrForBltLockSt1 "State of belt lock at driver seating position Belt lock state, locked/unlocked";
CM_ SG_ 305 BltLockStAtDrvrForDevErrSts2 "State of belt lock at driver seating position Belt lock status, OK/NOK";
CM_ SG_ 305 BltLockStAtPassForBltLockSt1 "State of belt lock at passenger seating position Belt lock state, locked/unlocked";
CM_ SG_ 305 BltLockStAtPassForBltLockSts "State of belt lock at passenger seating position Belt lock status, OK/NOK";
CM_ SG_ 305 BltLockStAtRowSecLeForBltLockEquid "State of belt lock at seating position at left of second row If the belt lock is equipped";
CM_ SG_ 305 BltLockStAtRowSecLeForBltLockSt1 "State of belt lock at seating position at left of second row Belt lock state,  locked/unlocked";
CM_ SG_ 305 BltLockStAtRowSecLeForBltLockSts "State of belt lock at seating position at left of second row Belt lock status, OK/NOK";
CM_ SG_ 305 BltLockStAtRowSecRiForBltLockEquid "State of belt lock at seating position at right of second row If the belt lock is equipped";
CM_ SG_ 305 BltLockStAtRowSecRiForBltLockSt1 "State of belt lock at seating position at right of second row Belt lock state,  locked/unlocked";
CM_ SG_ 305 BltLockStAtRowSecRiForBltLockSts "State of belt lock at seating position at right of second row Belt lock status, OK/NOK";
CM_ SG_ 305 DoorPassRePosnStsToAPIPassReDoorPosnSts " Position status of the rear passenger door";
CM_ SG_ 305 DoorPassRePosnStsToAPIPassReDoorPosnStsChks " Checksum for position status of rear passenger door";
CM_ SG_ 305 DoorPassRePosnStsToAPIPassReDoorPosnStsCntr " Counter for position status of rear passenger door";
CM_ SG_ 53 BrkPedlValBrkPedlVal "Position of the brake pedal.
physical lower limit: no pedal activation
physical upper limit: full pedal stroke Brake pedal position";
CM_ SG_ 53 BrkPedlValBrkPedlValQf "Position of the brake pedal.
physical lower limit: no pedal activation
physical upper limit: full pedal stroke Brake pedal sensor quality factor";
CM_ SG_ 53 ClstrSts2ForAutnmsDrvClstr2Chks "Cluster2 Status. CheckSum";
CM_ SG_ 53 ClstrSts2ForAutnmsDrvClstr2Cnt "Cluster2 Status. Counter";
CM_ SG_ 53 ClstrSts2ForAutnmsDrvClstr2Sts "Cluster2 Status. LV Cluster 2 Status";
CM_ SG_ 53 ExtDcDcActvnAllwd "External DCDCs 2nd (Backup) and 3rd (Redundant) activation and deactivation request to UBER.";
CM_ SG_ 53 PtTqAtAxleAvlFrntMax "Available propulsion maximum torque at front wheel axle, mean value of right and left wheels. Sign definition: A positive torque will accelerate the vehicle in the driver desired direction. 
";
CM_ SG_ 53 PtTqAtAxleAvlReMax "Available propulsion maximum torque at rear wheel axle, mean value of right and left wheels. Sign definition: A positive torque will accelerate the vehicle in the driver desired direction. 
";
CM_ SG_ 277 AdActvnOkFromVehDyn "<17w16d2 mnordstr>: Related requirement from FR AD: 

- AD VDM: Provide vehicle dynamics availability information v4 (url:swap://SystemWeaver:3000/x0400000000ECB82C)";
CM_ SG_ 277 AutnmsDrvModMngtGlbSafe1AutnmsDrvModSts1 "Data element communicates if Autonomous Drive status, Vehicle Operator present and RFAP mode activated or not with E2E protection. If Autonomous Drive is activated or not.";
CM_ SG_ 277 AutnmsDrvModMngtGlbSafe1AutnmsLowSpdModSts1 "Data element communicates if Autonomous Drive status, Vehicle Operator present and RFAP mode activated or not with E2E protection. If automatic parking is activated or not";
CM_ SG_ 277 AutnmsDrvModMngtGlbSafe1Checksum "Data element communicates if Autonomous Drive status, Vehicle Operator present and RFAP mode activated or not with E2E protection. Checksum used for E2E protection.";
CM_ SG_ 277 AutnmsDrvModMngtGlbSafe1Counter "Data element communicates if Autonomous Drive status, Vehicle Operator present and RFAP mode activated or not with E2E protection. Counter used for E2E protection.";
CM_ SG_ 277 AutnmsDrvModMngtGlbSafe1VehOperModSts1 "Data element communicates if Autonomous Drive status, Vehicle Operator present and RFAP mode activated or not with E2E protection. If VehicleOperatorMode is activated or not";
CM_ SG_ 277 EngFltIndcnEngFltIndcn1 "Text messages sent to DIM for Powertrain faults";
CM_ SG_ 277 EngFltIndcnEngFltIndcn10 "Text messages sent to DIM for Powertrain faults";
CM_ SG_ 277 EngFltIndcnEngFltIndcn11 "Text messages sent to DIM for Powertrain faults";
CM_ SG_ 277 EngFltIndcnEngFltIndcn12 "Text messages sent to DIM for Powertrain faults";
CM_ SG_ 277 EngFltIndcnEngFltIndcn13 "Text messages sent to DIM for Powertrain faults";
CM_ SG_ 277 EngFltIndcnEngFltIndcn14 "Text messages sent to DIM for Powertrain faults";
CM_ SG_ 277 EngFltIndcnEngFltIndcn15 "Text messages sent to DIM for Powertrain faults";
CM_ SG_ 277 EngFltIndcnEngFltIndcn16 "Text messages sent to DIM for Powertrain faults";
CM_ SG_ 277 EngFltIndcnEngFltIndcn17 "Text messages sent to DIM for Powertrain faults";
CM_ SG_ 277 EngFltIndcnEngFltIndcn18 "Text messages sent to DIM for Powertrain faults";
CM_ SG_ 277 EngFltIndcnEngFltIndcn19 "Text messages sent to DIM for Powertrain faults";
CM_ SG_ 277 EngFltIndcnEngFltIndcn2 "Text messages sent to DIM for Powertrain faults";
CM_ SG_ 277 EngFltIndcnEngFltIndcn20 "Text messages sent to DIM for Powertrain faults";
CM_ SG_ 277 EngFltIndcnEngFltIndcn21 "Text messages sent to DIM for Powertrain faults";
CM_ SG_ 277 EngFltIndcnEngFltIndcn22 "Text messages sent to DIM for Powertrain faults";
CM_ SG_ 277 EngFltIndcnEngFltIndcn23 "Text messages sent to DIM for Powertrain faults";
CM_ SG_ 277 EngFltIndcnEngFltIndcn24 "Text messages sent to DIM for Powertrain faults";
CM_ SG_ 277 EngFltIndcnEngFltIndcn25 "Text messages sent to DIM for Powertrain faults";
CM_ SG_ 277 EngFltIndcnEngFltIndcn26 "Text messages sent to DIM for Powertrain faults";
CM_ SG_ 277 EngFltIndcnEngFltIndcn27 "Text messages sent to DIM for Powertrain faults";
CM_ SG_ 277 EngFltIndcnEngFltIndcn3 "Text messages sent to DIM for Powertrain faults";
CM_ SG_ 277 EngFltIndcnEngFltIndcn4 "Text messages sent to DIM for Powertrain faults";
CM_ SG_ 277 EngFltIndcnEngFltIndcn5 "Text messages sent to DIM for Powertrain faults";
CM_ SG_ 277 EngFltIndcnEngFltIndcn6 "Text messages sent to DIM for Powertrain faults";
CM_ SG_ 277 EngFltIndcnEngFltIndcn7 "Text messages sent to DIM for Powertrain faults";
CM_ SG_ 277 EngFltIndcnEngFltIndcn8 "Text messages sent to DIM for Powertrain faults";
CM_ SG_ 277 EngFltIndcnEngFltIndcn9 "Text messages sent to DIM for Powertrain faults";
CM_ SG_ 277 PtTqAtAxleAvlReMaxLong "Maximum propulsive torque capability at rear wheel axle long horizon.";

// Attribute definitions
BA_DEF_  "Baudrate" INT 1000 1000000; // [bps]
BA_DEF_  "BusType" STRING;
BA_DEF_  "DBName" STRING;
BA_DEF_  "ProtocolType" STRING;
BA_DEF_ BU_ "NmAsrNode" ENUM "No","Yes";
BA_DEF_ BU_ "NmAsrNodeIdentifier" INT 0 255;
BA_DEF_ BO_ "GenMsgCycleTime" INT 0 65536; // [ms]
BA_DEF_ BO_ "GenMsgDelayTime" INT 0 65536; // [ms]
BA_DEF_ BO_ "GenMsgSendType" ENUM "cyclic", "spontaneous", "not-used", "not-used", "not-used", "cyclicAndSpontaneous", "not-used", "cyclicIfActive", "NoMsgSendType"; // [us]
BA_DEF_ BO_ "GenMsgStartDelayTime" INT 0 65536; // [ms]
BA_DEF_ SG_ "GenSigSendType" ENUM "Cyclic","OnWrite","OnWriteWithRepetition","OnChange","OnChangeWithRepetition","IfActive","IfActiveWithRepetition","NoSigSendType";
BA_DEF_ SG_ "GenSigStartValue" HEX 0 80000000;
BA_DEF_ BO_ "GenMsgILSupport" ENUM "No","Yes";
BA_DEF_ BO_ "NmAsrMessage" ENUM "No","Yes";
BA_DEF_  "NmAsrBaseAddress" HEX 0 536870911;
BA_DEF_  "NmAsrMessageCount" INT 0 255;
BA_DEF_ BU_ "NodeLayerModules" STRING;
BA_DEF_ BU_ "ILused" ENUM "No","Yes";
BA_DEF_ SG_ "GenSigFuncType" ENUM "NoFunction","n/a","n/a","n/a","n/a","n/a","n/a","n/a","n/a","n/a","n/a","n/a","n/a","n/a","n/a","CHK","CNTR","n/a","n/a","n/a","CNTR_AR_01","CRC_AR_01_BOTH","CRC_AR_01_ALT","CRC_AR_01_LOW","CRC_AR_01_NIBBLE","CNTR_AR_04","CRC_AR_04A","CNTR_AR_05","CRC_AR_05";
BA_DEF_ SG_ "GenSigDataID" STRING;
BA_DEF_ SG_ "SigGroup" STRING;

BA_DEF_DEF_ "BusType" "";
BA_DEF_DEF_ "DBName" "";
BA_DEF_DEF_ "ProtocolType" "";
BA_DEF_DEF_ "NmAsrNode" "No";
BA_DEF_DEF_ "NmAsrNodeIdentifier" 0;
BA_DEF_DEF_ "GenSigStartValue" 0;
BA_DEF_DEF_ "GenSigSendType" "NoSigSendType";
BA_DEF_DEF_ "GenMsgCycleTime" 0;
BA_DEF_DEF_ "GenMsgDelayTime" 0;
BA_DEF_DEF_ "GenMsgStartDelayTime" 0;
BA_DEF_DEF_ "GenMsgSendType" "NoMsgSendType";
BA_DEF_DEF_ "GenMsgILSupport" "Yes";
BA_DEF_DEF_ "NmAsrMessage" "No";
BA_DEF_DEF_ "NmAsrBaseAddress" 1280;
BA_DEF_DEF_ "NmAsrMessageCount" 64;
BA_DEF_DEF_ "NodeLayerModules" "CANoeILNLSPA.dll";
BA_DEF_DEF_ "ILused" "Yes";
BA_DEF_DEF_ "GenSigFuncType" "NoFunction";
BA_DEF_DEF_ "GenSigDataID" "";
BA_DEF_DEF_ "SigGroup" "";

BA_ "Baudrate" 500000;
BA_ "BusType" "CAN";
BA_ "DBName" "Mid3Can";
BA_ "ProtocolType" "CAN";
// Network
// ECU: ETC
BA_ "ILused" BU_ ETC 0;
// ECU: SSM
BA_ "NmAsrNode" BU_ SSM 1;
BA_ "NmAsrNodeIdentifier" BU_ SSM 7;
BA_ "NodeLayerModules" BU_ SSM "CANoeILNLSPA.dll,AsrNM33.dll";
// ECU: VCU1
BA_ "NmAsrNode" BU_ VCU1 1;
BA_ "NmAsrNodeIdentifier" BU_ VCU1 3;
BA_ "NodeLayerModules" BU_ VCU1 "CANoeILNLSPA.dll,AsrNM33.dll";
// ECU: VIM
BA_ "NmAsrNode" BU_ VIM 1;
BA_ "NmAsrNodeIdentifier" BU_ VIM 8;
BA_ "NodeLayerModules" BU_ VIM "CANoeILNLSPA.dll,AsrNM33.dll";
// ECU: VIMB
BA_ "ILused" BU_ VIMB 0;
// Frame: ETCVCU1DevSendMid3Fr1
BA_ "GenMsgDelayTime" BO_ 1408 10.000;
BA_ "GenMsgSendType" BO_ 1408 1;
// Frame: ETCVCU1DevSendMid3Fr2
BA_ "GenMsgDelayTime" BO_ 1409 10.000;
BA_ "GenMsgSendType" BO_ 1409 1;
// Frame: ETCVCU1DevSendMid3Fr3
BA_ "GenMsgDelayTime" BO_ 1410 10.000;
BA_ "GenMsgSendType" BO_ 1410 1;
// Frame: ETCVCU1DevSendMid3Fr4
BA_ "GenMsgDelayTime" BO_ 1411 10.000;
BA_ "GenMsgSendType" BO_ 1411 1;
// Frame: ETCVCU1DevSendMid3Fr5
BA_ "GenMsgDelayTime" BO_ 1412 10.000;
BA_ "GenMsgSendType" BO_ 1412 1;
// Frame: SSMMid3CanFr01
BA_ "GenMsgCycleTime" BO_ 262 45.000;
BA_ "GenMsgSendType" BO_ 262 0;
// Frame: SSMMid3CanFr02
BA_ "GenMsgCycleTime" BO_ 55 10.000;
BA_ "GenMsgSendType" BO_ 55 0;
// Frame: SSMMid3CanFr07
BA_ "GenMsgCycleTime" BO_ 99 40.000;
BA_ "GenMsgSendType" BO_ 99 0;
// Frame: SSMMid3CanFr11
BA_ "GenMsgCycleTime" BO_ 52 10.000;
BA_ "GenMsgSendType" BO_ 52 0;
// Frame: SsmMid3CanNmFr
BA_ "GenMsgDelayTime" BO_ 1287 20.000;
BA_ "GenMsgSendType" BO_ 1287 1;
// Frame: VCU1DevSendMid3Fr1
BA_ "GenMsgDelayTime" BO_ 1413 10.000;
BA_ "GenMsgSendType" BO_ 1413 1;
// Frame: VCU1DevSendMid3Fr2
BA_ "GenMsgDelayTime" BO_ 1414 10.000;
BA_ "GenMsgSendType" BO_ 1414 1;
// Frame: VCU1DevSendMid3Fr3
BA_ "GenMsgDelayTime" BO_ 1415 10.000;
BA_ "GenMsgSendType" BO_ 1415 1;
// Frame: VCU1DevSendMid3Fr4
BA_ "GenMsgDelayTime" BO_ 1416 10.000;
BA_ "GenMsgSendType" BO_ 1416 1;
// Frame: VCU1DevSendMid3Fr5
BA_ "GenMsgDelayTime" BO_ 1417 10.000;
BA_ "GenMsgSendType" BO_ 1417 1;
// Frame: VCU1Mid3CanFr01
BA_ "GenMsgCycleTime" BO_ 48 10.000;
BA_ "GenMsgSendType" BO_ 48 0;
// Frame: VCU1Mid3CanFr02
BA_ "GenMsgCycleTime" BO_ 64 10.000;
BA_ "GenMsgSendType" BO_ 64 0;
// Frame: VCU1Mid3CanFr03
BA_ "GenMsgCycleTime" BO_ 85 20.000;
BA_ "GenMsgSendType" BO_ 85 0;
// Frame: VCU1Mid3CanFr04
BA_ "GenMsgCycleTime" BO_ 98 40.000;
BA_ "GenMsgSendType" BO_ 98 0;
// Frame: VCU1Mid3CanFr05
BA_ "GenMsgCycleTime" BO_ 153 95.000;
BA_ "GenMsgSendType" BO_ 153 0;
// Frame: VCU1Mid3CanFr06
BA_ "GenMsgCycleTime" BO_ 896 380.000;
BA_ "GenMsgSendType" BO_ 896 0;
// Frame: VCU1Mid3CanFr08
BA_ "GenMsgCycleTime" BO_ 57 10.000;
BA_ "GenMsgSendType" BO_ 57 0;
// Frame: VCU1Mid3CanFr09
BA_ "GenMsgCycleTime" BO_ 73 15.000;
BA_ "GenMsgSendType" BO_ 73 0;
// Frame: VCU1Mid3CanFr10
BA_ "GenMsgCycleTime" BO_ 304 260.000;
BA_ "GenMsgSendType" BO_ 304 0;
// Frame: VCU1Mid3CanFr11
BA_ "GenMsgCycleTime" BO_ 305 260.000;
BA_ "GenMsgSendType" BO_ 305 0;
// Frame: VCU1Mid3CanFr12
BA_ "GenMsgCycleTime" BO_ 53 10.000;
BA_ "GenMsgSendType" BO_ 53 0;
// Frame: VCU1Mid3CanFr13
BA_ "GenMsgCycleTime" BO_ 277 50.000;
BA_ "GenMsgSendType" BO_ 277 0;
BA_ "GenMsgILSupport" BO_ 1287 0;
BA_ "NmAsrMessage" BO_ 1287 1;
BA_ "GenSigStartValue" SG_ 48 AdPrimSteerStsSafeGroupAdSteerPerf 20;
BA_ "GenSigDataID" SG_ 48 AdPrimSteerStsSafeGroupChks "0x1A0";
BA_ "GenSigFuncType" SG_ 48 AdPrimSteerStsSafeGroupChks 15;
BA_ "GenSigFuncType" SG_ 48 AdPrimSteerStsSafeGroupCntr 16;
BA_ "GenSigDataID" SG_ 153 AdSecBlindStopMonActvnGroupSafeChks "0x26E";
BA_ "GenSigFuncType" SG_ 153 AdSecBlindStopMonActvnGroupSafeChks 15;
BA_ "GenSigFuncType" SG_ 153 AdSecBlindStopMonActvnGroupSafeCntr 16;
BA_ "GenSigDataID" SG_ 85 AdSecSteerActvnGroupSafeChks "0x1A7";
BA_ "GenSigFuncType" SG_ 85 AdSecSteerActvnGroupSafeChks 15;
BA_ "GenSigFuncType" SG_ 85 AdSecSteerActvnGroupSafeCntr 16;
BA_ "GenSigStartValue" SG_ 262 AdSecSteerModStsSafeGroupByGatewyAdSteerMod 2;
BA_ "SigGroup" SG_ 262 AdSecSteerModStsSafeGroupByGatewyAdSteerMod "AdSecSteerModStsSafeGroupByGatewy";
BA_ "GenSigDataID" SG_ 262 AdSecSteerModStsSafeGroupByGatewyChks "0x407";
BA_ "GenSigFuncType" SG_ 262 AdSecSteerModStsSafeGroupByGatewyChks 15;
BA_ "SigGroup" SG_ 262 AdSecSteerModStsSafeGroupByGatewyChks "AdSecSteerModStsSafeGroupByGatewy";
BA_ "GenSigFuncType" SG_ 262 AdSecSteerModStsSafeGroupByGatewyCntr 16;
BA_ "SigGroup" SG_ 262 AdSecSteerModStsSafeGroupByGatewyCntr "AdSecSteerModStsSafeGroupByGatewy";
BA_ "SigGroup" SG_ 262 AdSecSteerModStsSafeGroupByGatewyVehOperIntv "AdSecSteerModStsSafeGroupByGatewy";
BA_ "SigGroup" SG_ 262 AdSecSteerModStsSafeGroupByGatewyVehOperModSts1 "AdSecSteerModStsSafeGroupByGatewy";
BA_ "GenSigStartValue" SG_ 262 AdSecSteerStsSafeGroupByGatewyAdSteerPerf 20;
BA_ "GenSigStartValue" SG_ 262 AdSecSteerStsSafeGroupByGatewyAdSteerSts 4;
BA_ "GenSigDataID" SG_ 262 AdSecSteerStsSafeGroupByGatewyChks "0x408";
BA_ "GenSigFuncType" SG_ 262 AdSecSteerStsSafeGroupByGatewyChks 15;
BA_ "GenSigFuncType" SG_ 262 AdSecSteerStsSafeGroupByGatewyCntr 16;
BA_ "GenSigDataID" SG_ 73 AdSteerPaddlPsdGroupSafeChks "0x404";
BA_ "GenSigFuncType" SG_ 73 AdSteerPaddlPsdGroupSafeChks 15;
BA_ "GenSigFuncType" SG_ 73 AdSteerPaddlPsdGroupSafeCntr 16;
BA_ "GenSigDataID" SG_ 57 AgDataRawSafeChks "0x23";
BA_ "GenSigFuncType" SG_ 57 AgDataRawSafeChks 15;
BA_ "GenSigStartValue" SG_ 57 AgDataRawSafeChks 255;
BA_ "GenSigFuncType" SG_ 57 AgDataRawSafeCntr 16;
BA_ "GenSigStartValue" SG_ 305 AhbcIndcnToAPI 2;
BA_ "GenSigStartValue" SG_ 305 BltLockStAtDrvrForBltLockSt1 1;
BA_ "GenSigStartValue" SG_ 305 BltLockStAtPassForBltLockSt1 1;
BA_ "GenSigStartValue" SG_ 305 BltLockStAtRowSecLeForBltLockEquid 1;
BA_ "GenSigStartValue" SG_ 305 BltLockStAtRowSecLeForBltLockSts 1;
BA_ "GenSigStartValue" SG_ 305 BltLockStAtRowSecRiForBltLockEquid 1;
BA_ "GenSigStartValue" SG_ 305 BltLockStAtRowSecRiForBltLockSts 1;
BA_ "GenSigStartValue" SG_ 53 BrkPedlValBrkPedlValQf 1;
BA_ "GenSigStartValue" SG_ 64 BrkTqMinReqBrkTqGrdtNegMinReq 1023;
BA_ "GenSigStartValue" SG_ 64 BrkTqMinReqBrkTqGrdtPosMinReq 1023;
BA_ "GenSigDataID" SG_ 64 BrkTqMinReqBrkTqMinReqChks "0x90";
BA_ "GenSigFuncType" SG_ 64 BrkTqMinReqBrkTqMinReqChks 15;
BA_ "GenSigFuncType" SG_ 64 BrkTqMinReqBrkTqMinReqCntr 16;
BA_ "GenSigDataID" SG_ 48 CarModInCrashStsSafeChks "0x261";
BA_ "GenSigFuncType" SG_ 48 CarModInCrashStsSafeChks 21;
BA_ "GenSigFuncType" SG_ 48 CarModInCrashStsSafeCntr 20;
BA_ "GenSigDataID" SG_ 57 ClstrSts1ForAutnmsDrvClstr1Chks "0x258";
BA_ "GenSigFuncType" SG_ 57 ClstrSts1ForAutnmsDrvClstr1Chks 15;
BA_ "GenSigDataID" SG_ 53 ClstrSts2ForAutnmsDrvClstr2Chks "0x259";
BA_ "GenSigFuncType" SG_ 53 ClstrSts2ForAutnmsDrvClstr2Chks 15;
BA_ "GenSigDataID" SG_ 304 DoorDrvrPosnStsToAPIDrvrDoorPosnStsChks "0x41B";
BA_ "GenSigFuncType" SG_ 304 DoorDrvrPosnStsToAPIDrvrDoorPosnStsChks 15;
BA_ "GenSigFuncType" SG_ 304 DoorDrvrPosnStsToAPIDrvrDoorPosnStsCntr 16;
BA_ "GenSigDataID" SG_ 304 DoorDrvrRePosnStsToAPIDrvrReDoorPosnStsChks "0x41C";
BA_ "GenSigFuncType" SG_ 304 DoorDrvrRePosnStsToAPIDrvrReDoorPosnStsChks 15;
BA_ "GenSigFuncType" SG_ 304 DoorDrvrRePosnStsToAPIDrvrReDoorPosnStsCntr 16;
BA_ "GenSigDataID" SG_ 304 DoorPassPosnStsToAPIPassDoorPosnStsChks "0x41D";
BA_ "GenSigFuncType" SG_ 304 DoorPassPosnStsToAPIPassDoorPosnStsChks 15;
BA_ "GenSigFuncType" SG_ 304 DoorPassPosnStsToAPIPassDoorPosnStsCntr 16;
BA_ "GenSigDataID" SG_ 305 DoorPassRePosnStsToAPIPassReDoorPosnStsChks "0x41E";
BA_ "GenSigFuncType" SG_ 305 DoorPassRePosnStsToAPIPassReDoorPosnStsChks 15;
BA_ "GenSigFuncType" SG_ 305 DoorPassRePosnStsToAPIPassReDoorPosnStsCntr 16;
BA_ "GenSigStartValue" SG_ 98 FricEstimnFromVehDynQly 1;
BA_ "GenSigDataID" SG_ 52 PrimALgtDataRawSafeChks "0x20F";
BA_ "GenSigFuncType" SG_ 52 PrimALgtDataRawSafeChks 15;
BA_ "GenSigFuncType" SG_ 52 PrimALgtDataRawSafeCntr 16;
BA_ "GenSigStartValue" SG_ 52 PrimALgtDataRawSafeMax 16384;
BA_ "GenSigStartValue" SG_ 52 PrimALgtDataRawSafeMin 16384;
BA_ "GenSigStartValue" SG_ 52 PrimALgtDataRawSafeNom 16384;
BA_ "GenSigStartValue" SG_ 52 PrimALgtDataRawSafeNomQf 1;
BA_ "GenSigDataID" SG_ 55 PrimSafeStopActv1Chks "0x780";
BA_ "GenSigFuncType" SG_ 55 PrimSafeStopActv1Chks 15;
BA_ "GenSigFuncType" SG_ 55 PrimSafeStopActv1Cntr 16;
BA_ "GenSigDataID" SG_ 99 PrimVehSpdGroupSafeChks "0x210";
BA_ "GenSigFuncType" SG_ 99 PrimVehSpdGroupSafeChks 15;
BA_ "GenSigFuncType" SG_ 99 PrimVehSpdGroupSafeCntr 16;
BA_ "GenSigStartValue" SG_ 99 PrimVehSpdGroupSafeNomQf 1;
BA_ "GenSigDataID" SG_ 85 PrpsnTqDirChks "0xA4";
BA_ "GenSigFuncType" SG_ 85 PrpsnTqDirChks 15;
BA_ "GenSigFuncType" SG_ 85 PrpsnTqDirCntr 16;
BA_ "GenSigDataID" SG_ 98 PrpsnTqDirCpbyChks "0x1CD";
BA_ "GenSigFuncType" SG_ 98 PrpsnTqDirCpbyChks 15;
BA_ "GenSigFuncType" SG_ 98 PrpsnTqDirCpbyCntr 16;
BA_ "GenSigStartValue" SG_ 57 RollRate1Qf1 1;
BA_ "GenSigStartValue" SG_ 73 SteerWhlSnsrQf 1;
BA_ "GenSigDataID" SG_ 73 SteerWhlSnsrSafeChks "0x33";
BA_ "GenSigFuncType" SG_ 73 SteerWhlSnsrSafeChks 15;
BA_ "GenSigFuncType" SG_ 73 SteerWhlSnsrSafeCntr 16;
BA_ "GenSigStartValue" SG_ 85 SteerWhlTqQf 1;
BA_ "GenSigSendType" SG_ 1408 VCU1DevReceiveMid3Fr1Byte0 1;
BA_ "GenSigSendType" SG_ 1408 VCU1DevReceiveMid3Fr1Byte1 1;
BA_ "GenSigSendType" SG_ 1408 VCU1DevReceiveMid3Fr1Byte2 1;
BA_ "GenSigSendType" SG_ 1408 VCU1DevReceiveMid3Fr1Byte3 1;
BA_ "GenSigSendType" SG_ 1408 VCU1DevReceiveMid3Fr1Byte4 1;
BA_ "GenSigSendType" SG_ 1408 VCU1DevReceiveMid3Fr1Byte5 1;
BA_ "GenSigSendType" SG_ 1408 VCU1DevReceiveMid3Fr1Byte6 1;
BA_ "GenSigSendType" SG_ 1408 VCU1DevReceiveMid3Fr1Byte7 1;
BA_ "GenSigSendType" SG_ 1409 VCU1DevReceiveMid3Fr2Byte0 1;
BA_ "GenSigSendType" SG_ 1409 VCU1DevReceiveMid3Fr2Byte1 1;
BA_ "GenSigSendType" SG_ 1409 VCU1DevReceiveMid3Fr2Byte2 1;
BA_ "GenSigSendType" SG_ 1409 VCU1DevReceiveMid3Fr2Byte3 1;
BA_ "GenSigSendType" SG_ 1409 VCU1DevReceiveMid3Fr2Byte4 1;
BA_ "GenSigSendType" SG_ 1409 VCU1DevReceiveMid3Fr2Byte5 1;
BA_ "GenSigSendType" SG_ 1409 VCU1DevReceiveMid3Fr2Byte6 1;
BA_ "GenSigSendType" SG_ 1409 VCU1DevReceiveMid3Fr2Byte7 1;
BA_ "GenSigSendType" SG_ 1410 VCU1DevReceiveMid3Fr3Byte0 1;
BA_ "GenSigSendType" SG_ 1410 VCU1DevReceiveMid3Fr3Byte1 1;
BA_ "GenSigSendType" SG_ 1410 VCU1DevReceiveMid3Fr3Byte2 1;
BA_ "GenSigSendType" SG_ 1410 VCU1DevReceiveMid3Fr3Byte3 1;
BA_ "GenSigSendType" SG_ 1410 VCU1DevReceiveMid3Fr3Byte4 1;
BA_ "GenSigSendType" SG_ 1410 VCU1DevReceiveMid3Fr3Byte5 1;
BA_ "GenSigSendType" SG_ 1410 VCU1DevReceiveMid3Fr3Byte6 1;
BA_ "GenSigSendType" SG_ 1410 VCU1DevReceiveMid3Fr3Byte7 1;
BA_ "GenSigSendType" SG_ 1411 VCU1DevReceiveMid3Fr4Byte0 1;
BA_ "GenSigSendType" SG_ 1411 VCU1DevReceiveMid3Fr4Byte1 1;
BA_ "GenSigSendType" SG_ 1411 VCU1DevReceiveMid3Fr4Byte2 1;
BA_ "GenSigSendType" SG_ 1411 VCU1DevReceiveMid3Fr4Byte3 1;
BA_ "GenSigSendType" SG_ 1411 VCU1DevReceiveMid3Fr4Byte4 1;
BA_ "GenSigSendType" SG_ 1411 VCU1DevReceiveMid3Fr4Byte5 1;
BA_ "GenSigSendType" SG_ 1411 VCU1DevReceiveMid3Fr4Byte6 1;
BA_ "GenSigSendType" SG_ 1411 VCU1DevReceiveMid3Fr4Byte7 1;
BA_ "GenSigSendType" SG_ 1412 VCU1DevReceiveMid3Fr5Byte0 1;
BA_ "GenSigSendType" SG_ 1412 VCU1DevReceiveMid3Fr5Byte1 1;
BA_ "GenSigSendType" SG_ 1412 VCU1DevReceiveMid3Fr5Byte2 1;
BA_ "GenSigSendType" SG_ 1412 VCU1DevReceiveMid3Fr5Byte3 1;
BA_ "GenSigSendType" SG_ 1412 VCU1DevReceiveMid3Fr5Byte4 1;
BA_ "GenSigSendType" SG_ 1412 VCU1DevReceiveMid3Fr5Byte5 1;
BA_ "GenSigSendType" SG_ 1412 VCU1DevReceiveMid3Fr5Byte6 1;
BA_ "GenSigSendType" SG_ 1412 VCU1DevReceiveMid3Fr5Byte7 1;
BA_ "GenSigSendType" SG_ 1413 VCU1DevSendMid3Fr1Byte0 1;
BA_ "GenSigSendType" SG_ 1413 VCU1DevSendMid3Fr1Byte1 1;
BA_ "GenSigSendType" SG_ 1413 VCU1DevSendMid3Fr1Byte2 1;
BA_ "GenSigSendType" SG_ 1413 VCU1DevSendMid3Fr1Byte3 1;
BA_ "GenSigSendType" SG_ 1413 VCU1DevSendMid3Fr1Byte4 1;
BA_ "GenSigSendType" SG_ 1413 VCU1DevSendMid3Fr1Byte5 1;
BA_ "GenSigSendType" SG_ 1413 VCU1DevSendMid3Fr1Byte6 1;
BA_ "GenSigSendType" SG_ 1413 VCU1DevSendMid3Fr1Byte7 1;
BA_ "GenSigSendType" SG_ 1414 VCU1DevSendMid3Fr2Byte0 1;
BA_ "GenSigSendType" SG_ 1414 VCU1DevSendMid3Fr2Byte1 1;
BA_ "GenSigSendType" SG_ 1414 VCU1DevSendMid3Fr2Byte2 1;
BA_ "GenSigSendType" SG_ 1414 VCU1DevSendMid3Fr2Byte3 1;
BA_ "GenSigSendType" SG_ 1414 VCU1DevSendMid3Fr2Byte4 1;
BA_ "GenSigSendType" SG_ 1414 VCU1DevSendMid3Fr2Byte5 1;
BA_ "GenSigSendType" SG_ 1414 VCU1DevSendMid3Fr2Byte6 1;
BA_ "GenSigSendType" SG_ 1414 VCU1DevSendMid3Fr2Byte7 1;
BA_ "GenSigSendType" SG_ 1415 VCU1DevSendMid3Fr3Byte0 1;
BA_ "GenSigSendType" SG_ 1415 VCU1DevSendMid3Fr3Byte1 1;
BA_ "GenSigSendType" SG_ 1415 VCU1DevSendMid3Fr3Byte2 1;
BA_ "GenSigSendType" SG_ 1415 VCU1DevSendMid3Fr3Byte3 1;
BA_ "GenSigSendType" SG_ 1415 VCU1DevSendMid3Fr3Byte4 1;
BA_ "GenSigSendType" SG_ 1415 VCU1DevSendMid3Fr3Byte5 1;
BA_ "GenSigSendType" SG_ 1415 VCU1DevSendMid3Fr3Byte6 1;
BA_ "GenSigSendType" SG_ 1415 VCU1DevSendMid3Fr3Byte7 1;
BA_ "GenSigSendType" SG_ 1416 VCU1DevSendMid3Fr4Byte0 1;
BA_ "GenSigSendType" SG_ 1416 VCU1DevSendMid3Fr4Byte1 1;
BA_ "GenSigSendType" SG_ 1416 VCU1DevSendMid3Fr4Byte2 1;
BA_ "GenSigSendType" SG_ 1416 VCU1DevSendMid3Fr4Byte3 1;
BA_ "GenSigSendType" SG_ 1416 VCU1DevSendMid3Fr4Byte4 1;
BA_ "GenSigSendType" SG_ 1416 VCU1DevSendMid3Fr4Byte5 1;
BA_ "GenSigSendType" SG_ 1416 VCU1DevSendMid3Fr4Byte6 1;
BA_ "GenSigSendType" SG_ 1416 VCU1DevSendMid3Fr4Byte7 1;
BA_ "GenSigSendType" SG_ 1417 VCU1DevSendMid3Fr5Byte0 1;
BA_ "GenSigSendType" SG_ 1417 VCU1DevSendMid3Fr5Byte1 1;
BA_ "GenSigSendType" SG_ 1417 VCU1DevSendMid3Fr5Byte2 1;
BA_ "GenSigSendType" SG_ 1417 VCU1DevSendMid3Fr5Byte3 1;
BA_ "GenSigSendType" SG_ 1417 VCU1DevSendMid3Fr5Byte4 1;
BA_ "GenSigSendType" SG_ 1417 VCU1DevSendMid3Fr5Byte5 1;
BA_ "GenSigSendType" SG_ 1417 VCU1DevSendMid3Fr5Byte6 1;
BA_ "GenSigSendType" SG_ 1417 VCU1DevSendMid3Fr5Byte7 1;
BA_ "GenSigStartValue" SG_ 153 VehMQly 1;
BA_ "GenSigStartValue" SG_ 304 WiprLvrStsIfWiprFrntSts 1;
BA_ "GenSigStartValue" SG_ 57 YawRate1Qf1 1;

VAL_ 262 AdSecSteerModStsSafeGroupByGatewyAdSteerMod 0 "AdSteerMod_Off" 1 "AdSteerMod_On" 2 "AdSteerMod_Unknown";
VAL_ 262 AdSecSteerModStsSafeGroupByGatewyVehOperIntv 0 "VehOperIntv_Off" 1 "VehOperIntv_On";
VAL_ 262 AdSecSteerModStsSafeGroupByGatewyVehOperModSts1 0 "VehOperModSts1_Ukwn" 1 "VehOperModSts1_NoVehOper" 2 "VehOperModSts1_VehOper";
VAL_ 262 AdSecSteerStsSafeGroupByGatewyAdSteerPerf 0 "AdSteerPerf_PerfLvl0" 1 "AdSteerPerf_PerfLvl1" 2 "AdSteerPerf_PerfLvl2" 3 "AdSteerPerf_PerfLvl3" 4 "AdSteerPerf_PerfLvl4" 5 "AdSteerPerf_PerfLvl5" 6 "AdSteerPerf_PerfLvl6" 7 "AdSteerPerf_PerfLvl7" 8 "AdSteerPerf_PerfLvl8" 9 "AdSteerPerf_PerfLvl9" 10 "AdSteerPerf_PerfLvl10" 11 "AdSteerPerf_PerfLvl11" 12 "AdSteerPerf_PerfLvl12" 13 "AdSteerPerf_PerfLvl13" 14 "AdSteerPerf_PerfLvl14" 15 "AdSteerPerf_PerfLvl15" 16 "AdSteerPerf_PerfLvl16" 17 "AdSteerPerf_PerfLvl17" 18 "AdSteerPerf_PerfLvl18" 19 "AdSteerPerf_PerfLvl19" 20 "AdSteerPerf_PerfLvl20";
VAL_ 262 AdSecSteerStsSafeGroupByGatewyAdSteerSts 0 "AdSteerSts_DegradedLvl4" 1 "AdSteerSts_DegradedLvl3" 2 "AdSteerSts_DegradedLvl2" 3 "AdSteerSts_DegradedLvl1" 4 "AdSteerSts_SysOK";
VAL_ 55 PrimSafeStopActv1PlatformSafeStopActv 0 "NoYes1_No" 1 "NoYes1_Yes";
VAL_ 99 PrimVehSpdGroupSafeMinMaxQf 0 "SafeQf_Ukwn" 1 "SafeQf_NoIntgrty" 2 "SafeQf_IntgrtyCmprmd" 3 "SafeQf_DataIntgrtyOK";
VAL_ 99 PrimVehSpdGroupSafeMovDir 0 "MovDir1_Ukwn" 1 "MovDir1_Standstill" 2 "MovDir1_NotStandstill" 3 "MovDir1_Fwd" 4 "MovDir1_Rvs" 5 "MovDir1_Err";
VAL_ 99 PrimVehSpdGroupSafeMovDirQf 0 "SafeQf_Ukwn" 1 "SafeQf_NoIntgrty" 2 "SafeQf_IntgrtyCmprmd" 3 "SafeQf_DataIntgrtyOK";
VAL_ 99 PrimVehSpdGroupSafeNomQf 0 "GenQf1_UndefindDataAccur" 1 "GenQf1_TmpUndefdData" 2 "GenQf1_DataAccurNotWithinSpcn" 3 "GenQf1_AccurData";
VAL_ 52 PrimALgtDataRawSafeMinMaxQf 0 "SafeQf_Ukwn" 1 "SafeQf_NoIntgrty" 2 "SafeQf_IntgrtyCmprmd" 3 "SafeQf_DataIntgrtyOK";
VAL_ 52 PrimALgtDataRawSafeNomQf 0 "GenQf1_UndefindDataAccur" 1 "GenQf1_TmpUndefdData" 2 "GenQf1_DataAccurNotWithinSpcn" 3 "GenQf1_AccurData";
VAL_ 48 AdPrimSteerStsSafeGroupAdSteerPerf 0 "AdSteerPerf_PerfLvl0" 1 "AdSteerPerf_PerfLvl1" 2 "AdSteerPerf_PerfLvl2" 3 "AdSteerPerf_PerfLvl3" 4 "AdSteerPerf_PerfLvl4" 5 "AdSteerPerf_PerfLvl5" 6 "AdSteerPerf_PerfLvl6" 7 "AdSteerPerf_PerfLvl7" 8 "AdSteerPerf_PerfLvl8" 9 "AdSteerPerf_PerfLvl9" 10 "AdSteerPerf_PerfLvl10" 11 "AdSteerPerf_PerfLvl11" 12 "AdSteerPerf_PerfLvl12" 13 "AdSteerPerf_PerfLvl13" 14 "AdSteerPerf_PerfLvl14" 15 "AdSteerPerf_PerfLvl15" 16 "AdSteerPerf_PerfLvl16" 17 "AdSteerPerf_PerfLvl17" 18 "AdSteerPerf_PerfLvl18" 19 "AdSteerPerf_PerfLvl19" 20 "AdSteerPerf_PerfLvl20";
VAL_ 48 AdPrimSteerStsSafeGroupAdSteerSts 0 "AdSteerSts_DegradedLvl4" 1 "AdSteerSts_DegradedLvl3" 2 "AdSteerSts_DegradedLvl2" 3 "AdSteerSts_DegradedLvl1" 4 "AdSteerSts_SysOK";
VAL_ 48 CarModInCrashStsSafeSts 0 "Boolean_FALSE" 1 "Boolean_TRUE";
VAL_ 64 BrkTqMinReqBrkActrCtrlModForMinTqReq 0 "BrkActrCtrlMod1_Norm" 1 "BrkActrCtrlMod1_Cmft" 2 "BrkActrCtrlMod1_Sfty" 3 "BrkActrCtrlMod1_VldForAd";
VAL_ 64 HornActvIf 0 "OnOffCrit1_NotVld1" 1 "OnOffCrit1_Off" 2 "OnOffCrit1_On" 3 "OnOffCrit1_NotVld2";
VAL_ 64 HornSwtStsIf 0 "OnOffCrit1_NotVld1" 1 "OnOffCrit1_Off" 2 "OnOffCrit1_On" 3 "OnOffCrit1_NotVld2";
VAL_ 85 AdSecSteerActvnGroupSafeAdSteerActvnReq 0 "OnOff1_Off" 1 "OnOff1_On";
VAL_ 85 AdSecSteerActvnGroupSafeAdSteerDeActvnReq 0 "OnOff1_Off" 1 "OnOff1_On";
VAL_ 85 PrpsnTqDirAct 0 "PrpsnDirAct1_Ukwn" 1 "PrpsnDirAct1_Fwd" 2 "PrpsnDirAct1_Rvs" 3 "PrpsnDirAct1_ZeroTorque";
VAL_ 85 SteerWhlTqQf 0 "GenQf1_UndefindDataAccur" 1 "GenQf1_TmpUndefdData" 2 "GenQf1_DataAccurNotWithinSpcn" 3 "GenQf1_AccurData";
VAL_ 98 FricEstimnFromVehDynQly 0 "Qly3_De0" 1 "Qly3_De1" 2 "Qly3_De2" 3 "Qly3_De3" 4 "Qly3_De4" 5 "Qly3_De5" 6 "Qly3_De6" 7 "Qly3_De7";
VAL_ 98 PrpsnTqDirCpbySts 0 "PrpsnTqDirCpby1_Ukwn" 1 "PrpsnTqDirCpby1_FullFcn" 2 "PrpsnTqDirCpby1_FwdOnly" 3 "PrpsnTqDirCpby1_RvsOnly" 4 "PrpsnTqDirCpby1_NoFcn";
VAL_ 98 SwtExtrLiToAPILiExtFctQf 0 "Qf1_DevOfDataUndefd" 1 "Qf1_DataTmpUndefdAndEvlnInProgs" 2 "Qf1_DevOfDataNotWithinRngAllwd" 3 "Qf1_DataCalcdWithDevDefd";
VAL_ 98 SwtExtrLiToAPILiExtFctReq1 0 "LiExtFctReq1_Off" 1 "LiExtFctReq1_Pos" 2 "LiExtFctReq1_Lo" 3 "LiExtFctReq1_AutLi";
VAL_ 153 AdSecBlindStopMonActvnGroupSafeActvnReq 0 "OnOff1_Off" 1 "OnOff1_On";
VAL_ 153 AdSecBlindStopMonActvnGroupSafeDeactvnReq 0 "OnOff1_Off" 1 "OnOff1_On";
VAL_ 153 DrvrGearShiftManReqDwnTipReq 0 "DwnTipReq_DwnTipReqNotActv" 1 "DwnTipReq_DwnTipReqActv";
VAL_ 153 DrvrGearShiftManReqSteerWhlDwnReq 0 "SteerWhlDwnReq1_SteerWhlDwnReqNotActv" 1 "SteerWhlDwnReq1_SteerWhlDwnReqActv";
VAL_ 153 DrvrGearShiftManReqSteerWhlUpReq 0 "SteerWhlUpReq_SteerWhlUpReqNotActv" 1 "SteerWhlUpReq_SteerWhlUpReqActv";
VAL_ 153 DrvrGearShiftManReqTipReq 0 "TipReq1_TipReqNotActv" 1 "TipReq1_TipReqActv";
VAL_ 153 DrvrGearShiftManReqUpTipReq 0 "UpTipReq1_UpTipReqNotActv" 1 "UpTipReq1_UpTipReqActv";
VAL_ 153 PassSeatSts 0 "PassSeatSts1_Empty" 1 "PassSeatSts1_Fmale" 2 "PassSeatSts1_OccptLrg" 3 "PassSeatSts1_Ukwn";
VAL_ 153 SnsrClngErrIfActr1 0 "DevErrSts2_NoFlt" 1 "DevErrSts2_Flt";
VAL_ 153 SnsrClngErrIfActr2 0 "DevErrSts2_NoFlt" 1 "DevErrSts2_Flt";
VAL_ 153 SnsrClngErrIfActr3 0 "DevErrSts2_NoFlt" 1 "DevErrSts2_Flt";
VAL_ 153 SnsrClngErrIfRsvd1 0 "DevErrSts2_NoFlt" 1 "DevErrSts2_Flt";
VAL_ 153 SnsrClngErrIfRsvd2 0 "DevErrSts2_NoFlt" 1 "DevErrSts2_Flt";
VAL_ 153 SnsrClngErrIfRsvd3 0 "DevErrSts2_NoFlt" 1 "DevErrSts2_Flt";
VAL_ 153 SnsrClngErrIfSysClngFailr 0 "DevErrSts2_NoFlt" 1 "DevErrSts2_Flt";
VAL_ 153 SnsrClngErrIfWshrFldSnsrFailr 0 "DevErrSts2_NoFlt" 1 "DevErrSts2_Flt";
VAL_ 153 VehMNomTrlrM 0 "TrlrM_Lvl0" 1 "TrlrM_Lvl1" 2 "TrlrM_Lvl2" 3 "TrlrM_Lvl3";
VAL_ 153 VehMQly 0 "Qly2_Flt" 1 "Qly2_NoInfo" 2 "Qly2_Vld";
VAL_ 153 WinWipgAutCmdIf 0 "WipgSpd2_WipgSpd0Rpm" 1 "WipgSpd2_WipgSpd40Rpm" 2 "WipgSpd2_WipgSpd43Rpm" 3 "WipgSpd2_WipgSpd46Rpm" 4 "WipgSpd2_WipgSpd50Rpm" 5 "WipgSpd2_WipgSpd54Rpm" 6 "WipgSpd2_WipgSpd57Rpm" 7 "WipgSpd2_WipgSpd60Rpm";
VAL_ 153 WipgFrntAutModIf 0 "WipgAutFrntMod_Off" 1 "WipgAutFrntMod_ImdtMod" 2 "WipgAutFrntMod_IntlMod" 3 "WipgAutFrntMod_ContnsMod";
VAL_ 153 WiprActvIf 0 "OnOff1_Off" 1 "OnOff1_On";
VAL_ 153 WshngCycActvIf 0 "OnOff1_Off" 1 "OnOff1_On";
VAL_ 57 ClstrSts1ForAutnmsDrvClstr1Sts 0 "StsAutnmsDrv_ADNotOk" 1 "StsAutnmsDrv_Degraded1" 2 "StsAutnmsDrv_Degraded2" 3 "StsAutnmsDrv_ADOk";
VAL_ 57 RollRate1Qf1 0 "Qf1_DevOfDataUndefd" 1 "Qf1_DataTmpUndefdAndEvlnInProgs" 2 "Qf1_DevOfDataNotWithinRngAllwd" 3 "Qf1_DataCalcdWithDevDefd";
VAL_ 57 YawRate1Qf1 0 "Qf1_DevOfDataUndefd" 1 "Qf1_DataTmpUndefdAndEvlnInProgs" 2 "Qf1_DevOfDataNotWithinRngAllwd" 3 "Qf1_DataCalcdWithDevDefd";
VAL_ 73 AdSteerPaddlPsdGroupSafeLe 0 "NoYes1_No" 1 "NoYes1_Yes";
VAL_ 73 AdSteerPaddlPsdGroupSafeLeSts 0 "OkNotOk_NotOk" 1 "OkNotOk_Ok";
VAL_ 73 AdSteerPaddlPsdGroupSafeRi 0 "NoYes1_No" 1 "NoYes1_Yes";
VAL_ 73 AdSteerPaddlPsdGroupSafeRiSts 0 "OkNotOk_NotOk" 1 "OkNotOk_Ok";
VAL_ 73 SteerWhlSnsrQf 0 "GenQf1_UndefindDataAccur" 1 "GenQf1_TmpUndefdData" 2 "GenQf1_DataAccurNotWithinSpcn" 3 "GenQf1_AccurData";
VAL_ 73 WhlMotSysCluSts 0 "EradCluSts1_CluOpen" 1 "EradCluSts1_CluClsd";
VAL_ 304 DoorDrvrPosnStsToAPIDrvrDoorPosnSts 0 "DoorPosnSts_Idle" 1 "DoorPosnSts_Unkwn" 2 "DoorPosnSts_FullClsd" 3 "DoorPosnSts_HalfClsd" 4 "DoorPosnSts_Opend" 5 "DoorPosnSts_MovgClsDir" 6 "DoorPosnSts_MovgOpenDir" 7 "DoorPosnSts_ManMovmtClsDir" 8 "DoorPosnSts_ManMovmtOpenDir" 9 "DoorPosnSts_PrepnForMovmt" 10 "DoorPosnSts_StopMinPntForCls";
VAL_ 304 DoorDrvrRePosnStsToAPIDrvrReDoorPosnSts 0 "DoorPosnSts_Idle" 1 "DoorPosnSts_Unkwn" 2 "DoorPosnSts_FullClsd" 3 "DoorPosnSts_HalfClsd" 4 "DoorPosnSts_Opend" 5 "DoorPosnSts_MovgClsDir" 6 "DoorPosnSts_MovgOpenDir" 7 "DoorPosnSts_ManMovmtClsDir" 8 "DoorPosnSts_ManMovmtOpenDir" 9 "DoorPosnSts_PrepnForMovmt" 10 "DoorPosnSts_StopMinPntForCls";
VAL_ 304 DoorPassPosnStsToAPIPassDoorPosnSts 0 "DoorPosnSts_Idle" 1 "DoorPosnSts_Unkwn" 2 "DoorPosnSts_FullClsd" 3 "DoorPosnSts_HalfClsd" 4 "DoorPosnSts_Opend" 5 "DoorPosnSts_MovgClsDir" 6 "DoorPosnSts_MovgOpenDir" 7 "DoorPosnSts_ManMovmtClsDir" 8 "DoorPosnSts_ManMovmtOpenDir" 9 "DoorPosnSts_PrepnForMovmt" 10 "DoorPosnSts_StopMinPntForCls";
VAL_ 304 EngCooltIndcnReqForExt 0 "EngCooltIndcn_MsgNoWarn" 1 "EngCooltIndcn_EngTHiToSpdRedn" 2 "EngCooltIndcn_EngTHiToStopSafe" 3 "EngCooltIndcn_EngTHiToEngStop" 4 "EngCooltIndcn_EngTHiToMan" 5 "EngCooltIndcn_CooltLvlLoToEngStop" 6 "EngCooltIndcn_CooltLvlLoToStopSafe" 7 "EngCooltIndcn_CooltLvlLoToMan" 8 "EngCooltIndcn_CooltLvlLoToLvlChk" 9 "EngCooltIndcn_MsgSrvRqrd";
VAL_ 304 WiprLvrStsIfWiprFrntSts 0 "WiprFrntReqIf_NotUsed" 1 "WiprFrntReqIf_FrntWiprOff" 2 "WiprFrntReqIf_FrntWiprSngStk" 3 "WiprFrntReqIf_FrntWiprIntm" 4 "WiprFrntReqIf_FrntWiprContnsLoSpd" 5 "WiprFrntReqIf_FrntWiprContnsHiSpd";
VAL_ 304 WiprLvrStsIfWiprReSts 0 "WiprReCmdIf_ReWiperRotyOff" 1 "WiprReCmdIf_ReWiprRotySng" 2 "WiprReCmdIf_ReWiprRotyIntm" 3 "WiprReCmdIf_ReWiprRotyContns";
VAL_ 305 AhbcIndcnToAPI 0 "AhbcSts1_Off" 1 "AhbcSts1_On" 2 "AhbcSts1_Unavailable";
VAL_ 305 BltLockStAtDrvrForBltLockSt1 0 "BltLockSt1_Unlock" 1 "BltLockSt1_Lock";
VAL_ 305 BltLockStAtDrvrForDevErrSts2 0 "DevErrSts2_NoFlt" 1 "DevErrSts2_Flt";
VAL_ 305 BltLockStAtPassForBltLockSt1 0 "BltLockSt1_Unlock" 1 "BltLockSt1_Lock";
VAL_ 305 BltLockStAtPassForBltLockSts 0 "DevErrSts2_NoFlt" 1 "DevErrSts2_Flt";
VAL_ 305 BltLockStAtRowSecLeForBltLockEquid 0 "CptEquid_Equid" 1 "CptEquid_NotEquid";
VAL_ 305 BltLockStAtRowSecLeForBltLockSt1 0 "BltLockSt1_Unlock" 1 "BltLockSt1_Lock";
VAL_ 305 BltLockStAtRowSecLeForBltLockSts 0 "DevErrSts2_NoFlt" 1 "DevErrSts2_Flt";
VAL_ 305 BltLockStAtRowSecRiForBltLockEquid 0 "CptEquid_Equid" 1 "CptEquid_NotEquid";
VAL_ 305 BltLockStAtRowSecRiForBltLockSt1 0 "BltLockSt1_Unlock" 1 "BltLockSt1_Lock";
VAL_ 305 BltLockStAtRowSecRiForBltLockSts 0 "DevErrSts2_NoFlt" 1 "DevErrSts2_Flt";
VAL_ 305 DoorDrvrMovmtFailNotif 0 "PwrDoorMovmtFailNotif_NoFailr" 1 "PwrDoorMovmtFailNotif_StopCmd" 2 "PwrDoorMovmtFailNotif_FctRelsNOK" 3 "PwrDoorMovmtFailNotif_VehPitchOrRollAgOutOfRng" 4 "PwrDoorMovmtFailNotif_VehSpdOutOfLim" 5 "PwrDoorMovmtFailNotif_AmbTOutOfRng" 6 "PwrDoorMovmtFailNotif_SplyUBelowLim" 7 "PwrDoorMovmtFailNotif_SplyUAboveLim" 8 "PwrDoorMovmtFailNotif_PosnRngMissmatch" 9 "PwrDoorMovmtFailNotif_EndPosnLim" 10 "PwrDoorMovmtFailNotif_RvsgMovmtFinshd" 11 "PwrDoorMovmtFailNotif_AntiCllsnSigDetd" 12 "PwrDoorMovmtFailNotif_AntiTrapSigDetd" 13 "PwrDoorMovmtFailNotif_ThermoProtnActvDetd" 14 "PwrDoorMovmtFailNotif_DoorMotStallCdn" 15 "PwrDoorMovmtFailNotif_DoorMotTiOut" 16 "PwrDoorMovmtFailNotif_AgSnsrFlt" 17 "PwrDoorMovmtFailNotif_DoorHallMotFlt" 18 "PwrDoorMovmtFailNotif_DoorMotDrvrGenFailr" 19 "PwrDoorMovmtFailNotif_LtchNotReldDetd" 20 "PwrDoorMovmtFailNotif_CluHndlgFailr" 21 "PwrDoorMovmtFailNotif_SysIninErr" 22 "PwrDoorMovmtFailNotif_NetErr" 23 "PwrDoorMovmtFailNotif_FctNotAvl" 24 "PwrDoorMovmtFailNotif_PrmSetInvld" 25 "PwrDoorMovmtFailNotif_GenMemFailr" 26 "PwrDoorMovmtFailNotif_TestModActv" 27 "PwrDoorMovmtFailNotif_NOKToClsDoor" 28 "PwrDoorMovmtFailNotif_NOKToOpenDoor" 29 "PwrDoorMovmtFailNotif_UsgModInvld";
VAL_ 305 DoorDrvrReMovmtFailNotif 0 "PwrDoorMovmtFailNotif_NoFailr" 1 "PwrDoorMovmtFailNotif_StopCmd" 2 "PwrDoorMovmtFailNotif_FctRelsNOK" 3 "PwrDoorMovmtFailNotif_VehPitchOrRollAgOutOfRng" 4 "PwrDoorMovmtFailNotif_VehSpdOutOfLim" 5 "PwrDoorMovmtFailNotif_AmbTOutOfRng" 6 "PwrDoorMovmtFailNotif_SplyUBelowLim" 7 "PwrDoorMovmtFailNotif_SplyUAboveLim" 8 "PwrDoorMovmtFailNotif_PosnRngMissmatch" 9 "PwrDoorMovmtFailNotif_EndPosnLim" 10 "PwrDoorMovmtFailNotif_RvsgMovmtFinshd" 11 "PwrDoorMovmtFailNotif_AntiCllsnSigDetd" 12 "PwrDoorMovmtFailNotif_AntiTrapSigDetd" 13 "PwrDoorMovmtFailNotif_ThermoProtnActvDetd" 14 "PwrDoorMovmtFailNotif_DoorMotStallCdn" 15 "PwrDoorMovmtFailNotif_DoorMotTiOut" 16 "PwrDoorMovmtFailNotif_AgSnsrFlt" 17 "PwrDoorMovmtFailNotif_DoorHallMotFlt" 18 "PwrDoorMovmtFailNotif_DoorMotDrvrGenFailr" 19 "PwrDoorMovmtFailNotif_LtchNotReldDetd" 20 "PwrDoorMovmtFailNotif_CluHndlgFailr" 21 "PwrDoorMovmtFailNotif_SysIninErr" 22 "PwrDoorMovmtFailNotif_NetErr" 23 "PwrDoorMovmtFailNotif_FctNotAvl" 24 "PwrDoorMovmtFailNotif_PrmSetInvld" 25 "PwrDoorMovmtFailNotif_GenMemFailr" 26 "PwrDoorMovmtFailNotif_TestModActv" 27 "PwrDoorMovmtFailNotif_NOKToClsDoor" 28 "PwrDoorMovmtFailNotif_NOKToOpenDoor" 29 "PwrDoorMovmtFailNotif_UsgModInvld";
VAL_ 305 DoorPassMovmtFailNotif 0 "PwrDoorMovmtFailNotif_NoFailr" 1 "PwrDoorMovmtFailNotif_StopCmd" 2 "PwrDoorMovmtFailNotif_FctRelsNOK" 3 "PwrDoorMovmtFailNotif_VehPitchOrRollAgOutOfRng" 4 "PwrDoorMovmtFailNotif_VehSpdOutOfLim" 5 "PwrDoorMovmtFailNotif_AmbTOutOfRng" 6 "PwrDoorMovmtFailNotif_SplyUBelowLim" 7 "PwrDoorMovmtFailNotif_SplyUAboveLim" 8 "PwrDoorMovmtFailNotif_PosnRngMissmatch" 9 "PwrDoorMovmtFailNotif_EndPosnLim" 10 "PwrDoorMovmtFailNotif_RvsgMovmtFinshd" 11 "PwrDoorMovmtFailNotif_AntiCllsnSigDetd" 12 "PwrDoorMovmtFailNotif_AntiTrapSigDetd" 13 "PwrDoorMovmtFailNotif_ThermoProtnActvDetd" 14 "PwrDoorMovmtFailNotif_DoorMotStallCdn" 15 "PwrDoorMovmtFailNotif_DoorMotTiOut" 16 "PwrDoorMovmtFailNotif_AgSnsrFlt" 17 "PwrDoorMovmtFailNotif_DoorHallMotFlt" 18 "PwrDoorMovmtFailNotif_DoorMotDrvrGenFailr" 19 "PwrDoorMovmtFailNotif_LtchNotReldDetd" 20 "PwrDoorMovmtFailNotif_CluHndlgFailr" 21 "PwrDoorMovmtFailNotif_SysIninErr" 22 "PwrDoorMovmtFailNotif_NetErr" 23 "PwrDoorMovmtFailNotif_FctNotAvl" 24 "PwrDoorMovmtFailNotif_PrmSetInvld" 25 "PwrDoorMovmtFailNotif_GenMemFailr" 26 "PwrDoorMovmtFailNotif_TestModActv" 27 "PwrDoorMovmtFailNotif_NOKToClsDoor" 28 "PwrDoorMovmtFailNotif_NOKToOpenDoor" 29 "PwrDoorMovmtFailNotif_UsgModInvld";
VAL_ 305 DoorPassReMovmtFailNotif 0 "PwrDoorMovmtFailNotif_NoFailr" 1 "PwrDoorMovmtFailNotif_StopCmd" 2 "PwrDoorMovmtFailNotif_FctRelsNOK" 3 "PwrDoorMovmtFailNotif_VehPitchOrRollAgOutOfRng" 4 "PwrDoorMovmtFailNotif_VehSpdOutOfLim" 5 "PwrDoorMovmtFailNotif_AmbTOutOfRng" 6 "PwrDoorMovmtFailNotif_SplyUBelowLim" 7 "PwrDoorMovmtFailNotif_SplyUAboveLim" 8 "PwrDoorMovmtFailNotif_PosnRngMissmatch" 9 "PwrDoorMovmtFailNotif_EndPosnLim" 10 "PwrDoorMovmtFailNotif_RvsgMovmtFinshd" 11 "PwrDoorMovmtFailNotif_AntiCllsnSigDetd" 12 "PwrDoorMovmtFailNotif_AntiTrapSigDetd" 13 "PwrDoorMovmtFailNotif_ThermoProtnActvDetd" 14 "PwrDoorMovmtFailNotif_DoorMotStallCdn" 15 "PwrDoorMovmtFailNotif_DoorMotTiOut" 16 "PwrDoorMovmtFailNotif_AgSnsrFlt" 17 "PwrDoorMovmtFailNotif_DoorHallMotFlt" 18 "PwrDoorMovmtFailNotif_DoorMotDrvrGenFailr" 19 "PwrDoorMovmtFailNotif_LtchNotReldDetd" 20 "PwrDoorMovmtFailNotif_CluHndlgFailr" 21 "PwrDoorMovmtFailNotif_SysIninErr" 22 "PwrDoorMovmtFailNotif_NetErr" 23 "PwrDoorMovmtFailNotif_FctNotAvl" 24 "PwrDoorMovmtFailNotif_PrmSetInvld" 25 "PwrDoorMovmtFailNotif_GenMemFailr" 26 "PwrDoorMovmtFailNotif_TestModActv" 27 "PwrDoorMovmtFailNotif_NOKToClsDoor" 28 "PwrDoorMovmtFailNotif_NOKToOpenDoor" 29 "PwrDoorMovmtFailNotif_UsgModInvld";
VAL_ 305 DoorPassRePosnStsToAPIPassReDoorPosnSts 0 "DoorPosnSts_Idle" 1 "DoorPosnSts_Unkwn" 2 "DoorPosnSts_FullClsd" 3 "DoorPosnSts_HalfClsd" 4 "DoorPosnSts_Opend" 5 "DoorPosnSts_MovgClsDir" 6 "DoorPosnSts_MovgOpenDir" 7 "DoorPosnSts_ManMovmtClsDir" 8 "DoorPosnSts_ManMovmtOpenDir" 9 "DoorPosnSts_PrepnForMovmt" 10 "DoorPosnSts_StopMinPntForCls";
VAL_ 53 BrkPedlValBrkPedlValQf 0 "GenQf1_UndefindDataAccur" 1 "GenQf1_TmpUndefdData" 2 "GenQf1_DataAccurNotWithinSpcn" 3 "GenQf1_AccurData";
VAL_ 53 ClstrSts2ForAutnmsDrvClstr2Sts 0 "StsAutnmsDrv_ADNotOk" 1 "StsAutnmsDrv_Degraded1" 2 "StsAutnmsDrv_Degraded2" 3 "StsAutnmsDrv_ADOk";
VAL_ 53 ExtDcDcActvnAllwd 0 "Boolean_FALSE" 1 "Boolean_TRUE";
VAL_ 277 AdActvnOkFromVehDyn 0 "OnOff1_Off" 1 "OnOff1_On";
VAL_ 277 AutnmsDrvModMngtGlbSafe1AutnmsDrvModSts1 0 "ActvSt_Idle" 1 "ActvSt_Actv" 2 "ActvSt_NotActv";
VAL_ 277 AutnmsDrvModMngtGlbSafe1AutnmsLowSpdModSts1 0 "ActvSt_Idle" 1 "ActvSt_Actv" 2 "ActvSt_NotActv";
VAL_ 277 AutnmsDrvModMngtGlbSafe1VehOperModSts1 0 "VehOperModSts1_Ukwn" 1 "VehOperModSts1_NoVehOper" 2 "VehOperModSts1_VehOper";
VAL_ 277 EngFltIndcnEngFltIndcn1 0 "DevErrSts2_NoFlt" 1 "DevErrSts2_Flt";
VAL_ 277 EngFltIndcnEngFltIndcn10 0 "DevErrSts2_NoFlt" 1 "DevErrSts2_Flt";
VAL_ 277 EngFltIndcnEngFltIndcn11 0 "DevErrSts2_NoFlt" 1 "DevErrSts2_Flt";
VAL_ 277 EngFltIndcnEngFltIndcn12 0 "DevErrSts2_NoFlt" 1 "DevErrSts2_Flt";
VAL_ 277 EngFltIndcnEngFltIndcn13 0 "DevErrSts2_NoFlt" 1 "DevErrSts2_Flt";
VAL_ 277 EngFltIndcnEngFltIndcn14 0 "DevErrSts2_NoFlt" 1 "DevErrSts2_Flt";
VAL_ 277 EngFltIndcnEngFltIndcn15 0 "DevErrSts2_NoFlt" 1 "DevErrSts2_Flt";
VAL_ 277 EngFltIndcnEngFltIndcn16 0 "DevErrSts2_NoFlt" 1 "DevErrSts2_Flt";
VAL_ 277 EngFltIndcnEngFltIndcn17 0 "DevErrSts2_NoFlt" 1 "DevErrSts2_Flt";
VAL_ 277 EngFltIndcnEngFltIndcn18 0 "DevErrSts2_NoFlt" 1 "DevErrSts2_Flt";
VAL_ 277 EngFltIndcnEngFltIndcn19 0 "DevErrSts2_NoFlt" 1 "DevErrSts2_Flt";
VAL_ 277 EngFltIndcnEngFltIndcn2 0 "DevErrSts2_NoFlt" 1 "DevErrSts2_Flt";
VAL_ 277 EngFltIndcnEngFltIndcn20 0 "DevErrSts2_NoFlt" 1 "DevErrSts2_Flt";
VAL_ 277 EngFltIndcnEngFltIndcn21 0 "DevErrSts2_NoFlt" 1 "DevErrSts2_Flt";
VAL_ 277 EngFltIndcnEngFltIndcn22 0 "DevErrSts2_NoFlt" 1 "DevErrSts2_Flt";
VAL_ 277 EngFltIndcnEngFltIndcn23 0 "DevErrSts2_NoFlt" 1 "DevErrSts2_Flt";
VAL_ 277 EngFltIndcnEngFltIndcn24 0 "DevErrSts2_NoFlt" 1 "DevErrSts2_Flt";
VAL_ 277 EngFltIndcnEngFltIndcn25 0 "DevErrSts2_NoFlt" 1 "DevErrSts2_Flt";
VAL_ 277 EngFltIndcnEngFltIndcn26 0 "DevErrSts2_NoFlt" 1 "DevErrSts2_Flt";
VAL_ 277 EngFltIndcnEngFltIndcn27 0 "DevErrSts2_NoFlt" 1 "DevErrSts2_Flt";
VAL_ 277 EngFltIndcnEngFltIndcn3 0 "DevErrSts2_NoFlt" 1 "DevErrSts2_Flt";
VAL_ 277 EngFltIndcnEngFltIndcn4 0 "DevErrSts2_NoFlt" 1 "DevErrSts2_Flt";
VAL_ 277 EngFltIndcnEngFltIndcn5 0 "DevErrSts2_NoFlt" 1 "DevErrSts2_Flt";
VAL_ 277 EngFltIndcnEngFltIndcn6 0 "DevErrSts2_NoFlt" 1 "DevErrSts2_Flt";
VAL_ 277 EngFltIndcnEngFltIndcn7 0 "DevErrSts2_NoFlt" 1 "DevErrSts2_Flt";
VAL_ 277 EngFltIndcnEngFltIndcn8 0 "DevErrSts2_NoFlt" 1 "DevErrSts2_Flt";
VAL_ 277 EngFltIndcnEngFltIndcn9 0 "DevErrSts2_NoFlt" 1 "DevErrSts2_Flt";
SIG_GROUP_ 48 AdPrimSteerStsSafeGroup 1 : AdPrimSteerStsSafeGroupAdSteerPerf AdPrimSteerStsSafeGroupAdSteerSts AdPrimSteerStsSafeGroupChks AdPrimSteerStsSafeGroupCntr;
SIG_GROUP_ 153 AdSecBlindStopMonActvnGroupSafe 1 : AdSecBlindStopMonActvnGroupSafeActvnReq AdSecBlindStopMonActvnGroupSafeChks AdSecBlindStopMonActvnGroupSafeCntr AdSecBlindStopMonActvnGroupSafeDeactvnReq;
SIG_GROUP_ 85 AdSecSteerActvnGroupSafe 1 : AdSecSteerActvnGroupSafeAdSteerActvnReq AdSecSteerActvnGroupSafeAdSteerDeActvnReq AdSecSteerActvnGroupSafeChks AdSecSteerActvnGroupSafeCntr;
SIG_GROUP_ 262 AdSecSteerModStsSafeGroupByGatewy 1 : AdSecSteerModStsSafeGroupByGatewyAdSteerMod AdSecSteerModStsSafeGroupByGatewyChks AdSecSteerModStsSafeGroupByGatewyCntr AdSecSteerModStsSafeGroupByGatewyVehOperIntv AdSecSteerModStsSafeGroupByGatewyVehOperModSts1;
SIG_GROUP_ 262 AdSecSteerStsSafeGroupByGatewy 1 : AdSecSteerStsSafeGroupByGatewyAdSteerPerf AdSecSteerStsSafeGroupByGatewyAdSteerSts AdSecSteerStsSafeGroupByGatewyChks AdSecSteerStsSafeGroupByGatewyCntr;
SIG_GROUP_ 73 AdSteerPaddlPsdGroupSafe 1 : AdSteerPaddlPsdGroupSafeChks AdSteerPaddlPsdGroupSafeCntr AdSteerPaddlPsdGroupSafeLe AdSteerPaddlPsdGroupSafeLeSts AdSteerPaddlPsdGroupSafeRi AdSteerPaddlPsdGroupSafeRiSts;
SIG_GROUP_ 57 AgDataRawSafe 1 : AgDataRawSafeChks AgDataRawSafeCntr RollRate1 RollRate1Qf1 YawRate1 YawRate1Qf1;
SIG_GROUP_ 277 AutnmsDrvModMngtGlbSafe1 1 : AutnmsDrvModMngtGlbSafe1AutnmsDrvModSts1 AutnmsDrvModMngtGlbSafe1AutnmsLowSpdModSts1 AutnmsDrvModMngtGlbSafe1Checksum AutnmsDrvModMngtGlbSafe1Counter AutnmsDrvModMngtGlbSafe1VehOperModSts1;
SIG_GROUP_ 305 BltLockStAtDrvr 1 : BltLockStAtDrvrForBltLockSt1 BltLockStAtDrvrForDevErrSts2;
SIG_GROUP_ 305 BltLockStAtPass 1 : BltLockStAtPassForBltLockSt1 BltLockStAtPassForBltLockSts;
SIG_GROUP_ 305 BltLockStAtRowSecLe 1 : BltLockStAtRowSecLeForBltLockEquid BltLockStAtRowSecLeForBltLockSt1 BltLockStAtRowSecLeForBltLockSts;
SIG_GROUP_ 305 BltLockStAtRowSecRi 1 : BltLockStAtRowSecRiForBltLockEquid BltLockStAtRowSecRiForBltLockSt1 BltLockStAtRowSecRiForBltLockSts;
SIG_GROUP_ 53 BrkPedlVal 1 : BrkPedlValBrkPedlVal BrkPedlValBrkPedlValQf;
SIG_GROUP_ 64 BrkTqMinReq 1 : BrkTqMinReqBrkActrCtrlModForMinTqReq BrkTqMinReqBrkTqGrdtNegMinReq BrkTqMinReqBrkTqGrdtPosMinReq BrkTqMinReqBrkTqMinReq BrkTqMinReqBrkTqMinReqChks BrkTqMinReqBrkTqMinReqCntr;
SIG_GROUP_ 48 CarModInCrashStsSafe 1 : CarModInCrashStsSafeChks CarModInCrashStsSafeCntr CarModInCrashStsSafeSts;
SIG_GROUP_ 57 ClstrSts1ForAutnmsDrv 1 : ClstrSts1ForAutnmsDrvClstr1Chks ClstrSts1ForAutnmsDrvClstr1Cnt ClstrSts1ForAutnmsDrvClstr1Sts;
SIG_GROUP_ 53 ClstrSts2ForAutnmsDrv 1 : ClstrSts2ForAutnmsDrvClstr2Chks ClstrSts2ForAutnmsDrvClstr2Cnt ClstrSts2ForAutnmsDrvClstr2Sts;
SIG_GROUP_ 304 DoorDrvrPosnStsToAPI 1 : DoorDrvrPosnStsToAPIDrvrDoorPosnSts DoorDrvrPosnStsToAPIDrvrDoorPosnStsChks DoorDrvrPosnStsToAPIDrvrDoorPosnStsCntr;
SIG_GROUP_ 304 DoorDrvrRePosnStsToAPI 1 : DoorDrvrRePosnStsToAPIDrvrReDoorPosnSts DoorDrvrRePosnStsToAPIDrvrReDoorPosnStsChks DoorDrvrRePosnStsToAPIDrvrReDoorPosnStsCntr;
SIG_GROUP_ 304 DoorPassPosnStsToAPI 1 : DoorPassPosnStsToAPIPassDoorPosnSts DoorPassPosnStsToAPIPassDoorPosnStsChks DoorPassPosnStsToAPIPassDoorPosnStsCntr;
SIG_GROUP_ 305 DoorPassRePosnStsToAPI 1 : DoorPassRePosnStsToAPIPassReDoorPosnSts DoorPassRePosnStsToAPIPassReDoorPosnStsChks DoorPassRePosnStsToAPIPassReDoorPosnStsCntr;
SIG_GROUP_ 153 DrvrGearShiftManReq 1 : DrvrGearShiftManReqDwnTipReq DrvrGearShiftManReqSteerWhlDwnReq DrvrGearShiftManReqSteerWhlUpReq DrvrGearShiftManReqTipReq DrvrGearShiftManReqUpTipReq;
SIG_GROUP_ 277 EngFltIndcn 1 : EngFltIndcnEngFltIndcn1 EngFltIndcnEngFltIndcn10 EngFltIndcnEngFltIndcn11 EngFltIndcnEngFltIndcn12 EngFltIndcnEngFltIndcn13 EngFltIndcnEngFltIndcn14 EngFltIndcnEngFltIndcn15 EngFltIndcnEngFltIndcn16 EngFltIndcnEngFltIndcn17 EngFltIndcnEngFltIndcn18 EngFltIndcnEngFltIndcn19 EngFltIndcnEngFltIndcn2 EngFltIndcnEngFltIndcn20 EngFltIndcnEngFltIndcn21 EngFltIndcnEngFltIndcn22 EngFltIndcnEngFltIndcn23 EngFltIndcnEngFltIndcn24 EngFltIndcnEngFltIndcn25 EngFltIndcnEngFltIndcn26 EngFltIndcnEngFltIndcn27 EngFltIndcnEngFltIndcn3 EngFltIndcnEngFltIndcn4 EngFltIndcnEngFltIndcn5 EngFltIndcnEngFltIndcn6 EngFltIndcnEngFltIndcn7 EngFltIndcnEngFltIndcn8 EngFltIndcnEngFltIndcn9;
SIG_GROUP_ 98 FricEstimnFromVehDynGroup 1 : FricEstimnFromVehDyn FricEstimnFromVehDynQly;
SIG_GROUP_ 52 PrimALgtDataRawSafe 1 : PrimALgtDataRawSafeChks PrimALgtDataRawSafeCntr PrimALgtDataRawSafeMax PrimALgtDataRawSafeMin PrimALgtDataRawSafeMinMaxQf PrimALgtDataRawSafeNom PrimALgtDataRawSafeNomQf;
SIG_GROUP_ 55 PrimSafeStopActv1 1 : PrimSafeStopActv1Chks PrimSafeStopActv1Cntr PrimSafeStopActv1PlatformSafeStopActv;
SIG_GROUP_ 99 PrimVehSpdGroupSafe 1 : PrimVehSpdGroupSafeChks PrimVehSpdGroupSafeCntr PrimVehSpdGroupSafeMax PrimVehSpdGroupSafeMin PrimVehSpdGroupSafeMinMaxQf PrimVehSpdGroupSafeMovDir PrimVehSpdGroupSafeMovDirQf PrimVehSpdGroupSafeNom PrimVehSpdGroupSafeNomQf;
SIG_GROUP_ 85 PrpsnTqDir 1 : PrpsnTqDirAct PrpsnTqDirChks PrpsnTqDirCntr;
SIG_GROUP_ 98 PrpsnTqDirCpby 1 : PrpsnTqDirCpbyChks PrpsnTqDirCpbyCntr PrpsnTqDirCpbySts;
SIG_GROUP_ 153 SnsrClngErrIf 1 : SnsrClngErrIfActr1 SnsrClngErrIfActr2 SnsrClngErrIfActr3 SnsrClngErrIfRsvd1 SnsrClngErrIfRsvd2 SnsrClngErrIfRsvd3 SnsrClngErrIfSysClngFailr SnsrClngErrIfWshrFldSnsrFailr;
SIG_GROUP_ 73 SteerWhlSnsr 1 : SteerWhlAgSafe SteerWhlAgSpdSafe SteerWhlSnsrQf SteerWhlSnsrSafeChks SteerWhlSnsrSafeCntr;
SIG_GROUP_ 85 SteerWhlTqGroup 1 : SteerWhlTq SteerWhlTqQf;
SIG_GROUP_ 98 SwtExtrLiToAPI 1 : SwtExtrLiToAPILiExtFctCntr SwtExtrLiToAPILiExtFctCrc SwtExtrLiToAPILiExtFctQf SwtExtrLiToAPILiExtFctReq1;
SIG_GROUP_ 1408 VCU1DevReceiveMid3Fr1 1 : VCU1DevReceiveMid3Fr1Byte0 VCU1DevReceiveMid3Fr1Byte1 VCU1DevReceiveMid3Fr1Byte2 VCU1DevReceiveMid3Fr1Byte3 VCU1DevReceiveMid3Fr1Byte4 VCU1DevReceiveMid3Fr1Byte5 VCU1DevReceiveMid3Fr1Byte6 VCU1DevReceiveMid3Fr1Byte7;
SIG_GROUP_ 1409 VCU1DevReceiveMid3Fr2 1 : VCU1DevReceiveMid3Fr2Byte0 VCU1DevReceiveMid3Fr2Byte1 VCU1DevReceiveMid3Fr2Byte2 VCU1DevReceiveMid3Fr2Byte3 VCU1DevReceiveMid3Fr2Byte4 VCU1DevReceiveMid3Fr2Byte5 VCU1DevReceiveMid3Fr2Byte6 VCU1DevReceiveMid3Fr2Byte7;
SIG_GROUP_ 1410 VCU1DevReceiveMid3Fr3 1 : VCU1DevReceiveMid3Fr3Byte0 VCU1DevReceiveMid3Fr3Byte1 VCU1DevReceiveMid3Fr3Byte2 VCU1DevReceiveMid3Fr3Byte3 VCU1DevReceiveMid3Fr3Byte4 VCU1DevReceiveMid3Fr3Byte5 VCU1DevReceiveMid3Fr3Byte6 VCU1DevReceiveMid3Fr3Byte7;
SIG_GROUP_ 1411 VCU1DevReceiveMid3Fr4 1 : VCU1DevReceiveMid3Fr4Byte0 VCU1DevReceiveMid3Fr4Byte1 VCU1DevReceiveMid3Fr4Byte2 VCU1DevReceiveMid3Fr4Byte3 VCU1DevReceiveMid3Fr4Byte4 VCU1DevReceiveMid3Fr4Byte5 VCU1DevReceiveMid3Fr4Byte6 VCU1DevReceiveMid3Fr4Byte7;
SIG_GROUP_ 1412 VCU1DevReceiveMid3Fr5 1 : VCU1DevReceiveMid3Fr5Byte0 VCU1DevReceiveMid3Fr5Byte1 VCU1DevReceiveMid3Fr5Byte2 VCU1DevReceiveMid3Fr5Byte3 VCU1DevReceiveMid3Fr5Byte4 VCU1DevReceiveMid3Fr5Byte5 VCU1DevReceiveMid3Fr5Byte6 VCU1DevReceiveMid3Fr5Byte7;
SIG_GROUP_ 1413 VCU1DevSendMid3Fr1 1 : VCU1DevSendMid3Fr1Byte0 VCU1DevSendMid3Fr1Byte1 VCU1DevSendMid3Fr1Byte2 VCU1DevSendMid3Fr1Byte3 VCU1DevSendMid3Fr1Byte4 VCU1DevSendMid3Fr1Byte5 VCU1DevSendMid3Fr1Byte6 VCU1DevSendMid3Fr1Byte7;
SIG_GROUP_ 1414 VCU1DevSendMid3Fr2 1 : VCU1DevSendMid3Fr2Byte0 VCU1DevSendMid3Fr2Byte1 VCU1DevSendMid3Fr2Byte2 VCU1DevSendMid3Fr2Byte3 VCU1DevSendMid3Fr2Byte4 VCU1DevSendMid3Fr2Byte5 VCU1DevSendMid3Fr2Byte6 VCU1DevSendMid3Fr2Byte7;
SIG_GROUP_ 1415 VCU1DevSendMid3Fr3 1 : VCU1DevSendMid3Fr3Byte0 VCU1DevSendMid3Fr3Byte1 VCU1DevSendMid3Fr3Byte2 VCU1DevSendMid3Fr3Byte3 VCU1DevSendMid3Fr3Byte4 VCU1DevSendMid3Fr3Byte5 VCU1DevSendMid3Fr3Byte6 VCU1DevSendMid3Fr3Byte7;
SIG_GROUP_ 1416 VCU1DevSendMid3Fr4 1 : VCU1DevSendMid3Fr4Byte0 VCU1DevSendMid3Fr4Byte1 VCU1DevSendMid3Fr4Byte2 VCU1DevSendMid3Fr4Byte3 VCU1DevSendMid3Fr4Byte4 VCU1DevSendMid3Fr4Byte5 VCU1DevSendMid3Fr4Byte6 VCU1DevSendMid3Fr4Byte7;
SIG_GROUP_ 1417 VCU1DevSendMid3Fr5 1 : VCU1DevSendMid3Fr5Byte0 VCU1DevSendMid3Fr5Byte1 VCU1DevSendMid3Fr5Byte2 VCU1DevSendMid3Fr5Byte3 VCU1DevSendMid3Fr5Byte4 VCU1DevSendMid3Fr5Byte5 VCU1DevSendMid3Fr5Byte6 VCU1DevSendMid3Fr5Byte7;
SIG_GROUP_ 153 VehMGroup 1 : VehM VehMNomTrlrM VehMQly;
SIG_GROUP_ 304 WiprLvrStsIf 1 : WiprLvrStsIfWiprFrntSts WiprLvrStsIfWiprReSts;
